AUTOSAR XML (schema 00048)
package /ComponentTypes
  swc implementation Can_Server_Implementation: behavior=Can_Server_InternalBehavior
    code-descriptors:
      code Default: artifact-descriptors=autosar-engineering-object=category=SWSRC
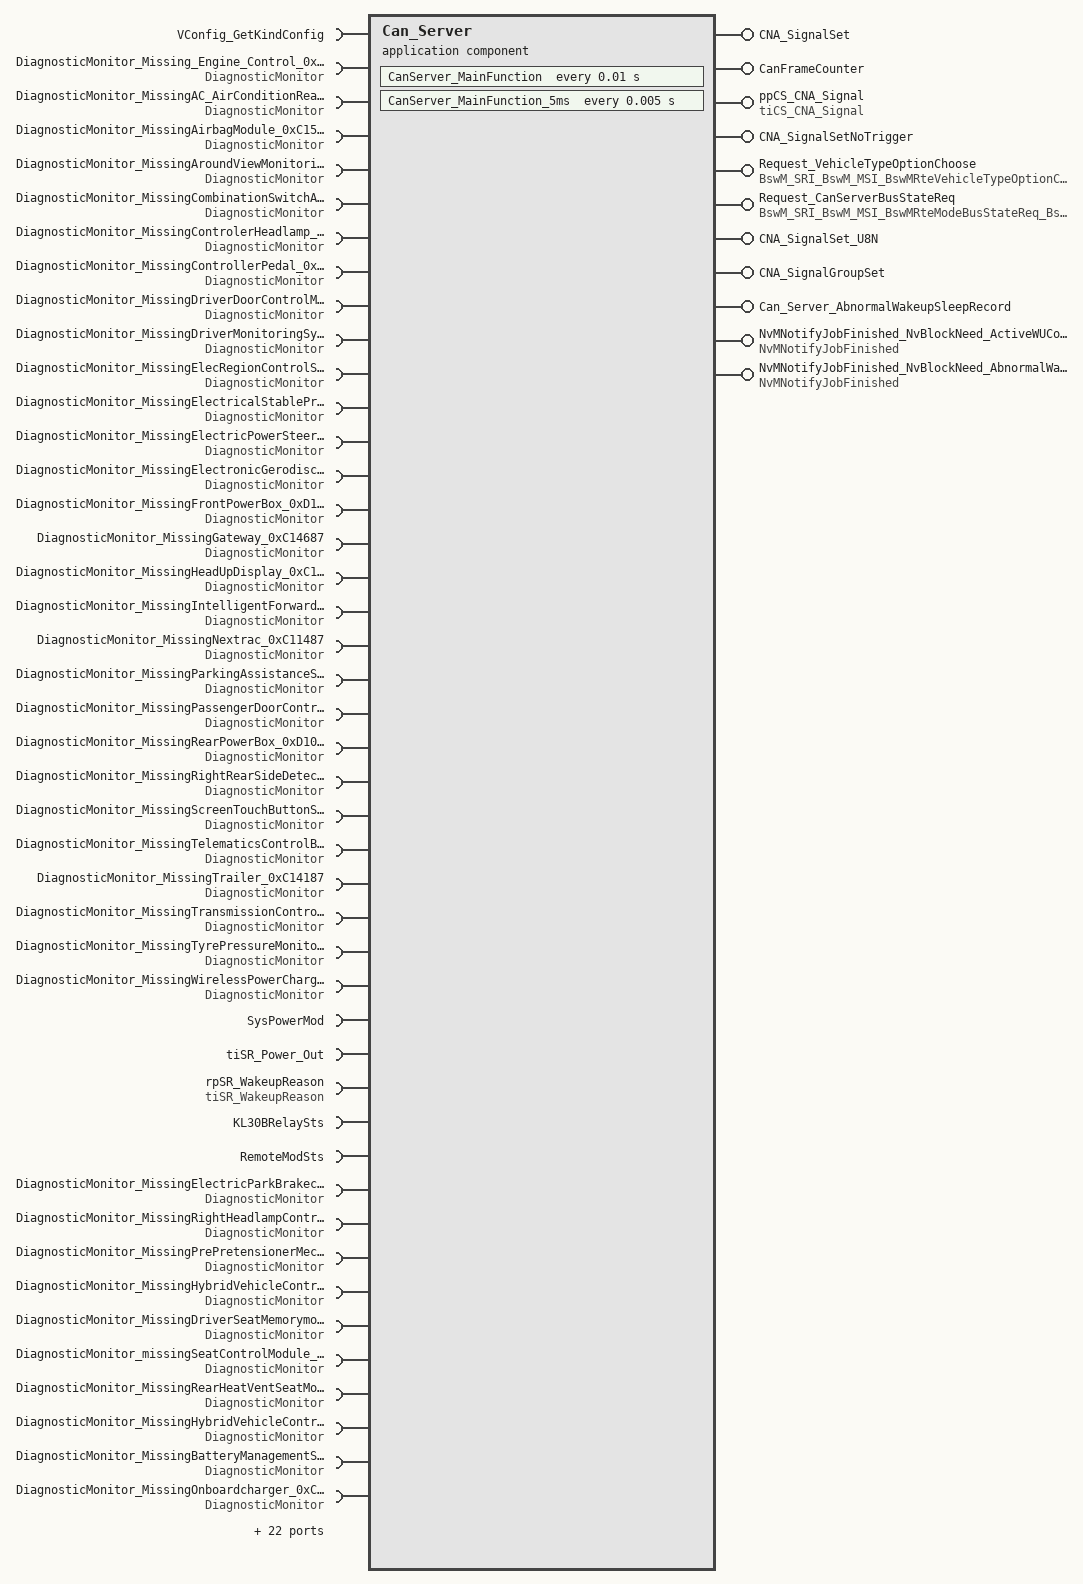
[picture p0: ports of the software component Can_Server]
  application sw component type Can_Server
    32 x require port:
      VConfig_GetKindConfig: client-com-spec=Operation_VConfig_GetKindConfig, required-interface=VConfig_GetKindConfig
      DiagnosticMonitor_Missing_Engine_Control_0xC10087: required-interface=DiagnosticMonitor
        required-com-specs:
          SetEventStatus
          ResetEventStatus
          ResetEventDebounceStatus
          GetEventUdsStatus
          GetEventStatus
          GetEventFailed
          GetEventTested
          GetDTCOfEvent
          GetFaultDetectionCounter
          GetEventFreezeFrameDataEx
          GetEventExtendedDataRecordEx
      DiagnosticMonitor_MissingAC_AirConditionRearFrontControlPanel_0xC16487: required-interface=DiagnosticMonitor
        required-com-specs:
          SetEventStatus
          ResetEventStatus
          ResetEventDebounceStatus
          GetEventUdsStatus
          GetEventStatus
          GetEventFailed
          GetEventTested
          GetDTCOfEvent
          GetFaultDetectionCounter
          GetEventFreezeFrameDataEx
          GetEventExtendedDataRecordEx
      DiagnosticMonitor_MissingAirbagModule_0xC15187: required-interface=DiagnosticMonitor
        required-com-specs:
          SetEventStatus
          ResetEventStatus
          ResetEventDebounceStatus
          GetEventUdsStatus
          GetEventStatus
          GetEventFailed
          GetEventTested
          GetDTCOfEvent
          GetFaultDetectionCounter
          GetEventFreezeFrameDataEx
          GetEventExtendedDataRecordEx
      DiagnosticMonitor_MissingAroundViewMonitoringSystem_0xD00487: required-interface=DiagnosticMonitor
        required-com-specs:
          SetEventStatus
          ResetEventStatus
          ResetEventDebounceStatus
          GetEventUdsStatus
          GetEventStatus
          GetEventFailed
          GetEventTested
          GetDTCOfEvent
          GetFaultDetectionCounter
          GetEventFreezeFrameDataEx
          GetEventExtendedDataRecordEx
      DiagnosticMonitor_MissingCombinationSwitchAssembly_0xD10687: required-interface=DiagnosticMonitor
        required-com-specs:
          SetEventStatus
          ResetEventStatus
          ResetEventDebounceStatus
          GetEventUdsStatus
          GetEventStatus
          GetEventFailed
          GetEventTested
          GetDTCOfEvent
          GetFaultDetectionCounter
          GetEventFreezeFrameDataEx
          GetEventExtendedDataRecordEx
      DiagnosticMonitor_MissingControlerHeadlamp_0xC24187: required-interface=DiagnosticMonitor
        required-com-specs:
          SetEventStatus
          ResetEventStatus
          ResetEventDebounceStatus
          GetEventUdsStatus
          GetEventStatus
          GetEventFailed
          GetEventTested
          GetDTCOfEvent
          GetFaultDetectionCounter
          GetEventFreezeFrameDataEx
          GetEventExtendedDataRecordEx
      DiagnosticMonitor_MissingControllerPedal_0xD00987: required-interface=DiagnosticMonitor
        required-com-specs:
          SetEventStatus
          ResetEventStatus
          ResetEventDebounceStatus
          GetEventUdsStatus
          GetEventStatus
          GetEventFailed
          GetEventTested
          GetDTCOfEvent
          GetFaultDetectionCounter
          GetEventFreezeFrameDataEx
          GetEventExtendedDataRecordEx
      DiagnosticMonitor_MissingDriverDoorControlModule_0xC19987: required-interface=DiagnosticMonitor
        required-com-specs:
          SetEventStatus
          ResetEventStatus
          ResetEventDebounceStatus
          GetEventUdsStatus
          GetEventStatus
          GetEventFailed
          GetEventTested
          GetDTCOfEvent
          GetFaultDetectionCounter
          GetEventFreezeFrameDataEx
          GetEventExtendedDataRecordEx
      DiagnosticMonitor_MissingDriverMonitoringSystem_0xC2B387: required-interface=DiagnosticMonitor
        required-com-specs:
          SetEventStatus
          ResetEventStatus
          ResetEventDebounceStatus
          GetEventUdsStatus
          GetEventStatus
          GetEventFailed
          GetEventTested
          GetDTCOfEvent
          GetFaultDetectionCounter
          GetEventFreezeFrameDataEx
          GetEventExtendedDataRecordEx
      DiagnosticMonitor_MissingElecRegionControlSystemBody_0xC14087: required-interface=DiagnosticMonitor
        required-com-specs:
          SetEventStatus
          ResetEventStatus
          ResetEventDebounceStatus
          GetEventUdsStatus
          GetEventStatus
          GetEventFailed
          GetEventTested
          GetDTCOfEvent
          GetFaultDetectionCounter
          GetEventFreezeFrameDataEx
          GetEventExtendedDataRecordEx
      DiagnosticMonitor_MissingElectricalStableProgram_0xC12287: required-interface=DiagnosticMonitor
        required-com-specs:
          SetEventStatus
          ResetEventStatus
          ResetEventDebounceStatus
          GetEventUdsStatus
          GetEventStatus
          GetEventFailed
          GetEventTested
          GetDTCOfEvent
          GetFaultDetectionCounter
          GetEventFreezeFrameDataEx
          GetEventExtendedDataRecordEx
      DiagnosticMonitor_MissingElectricPowerSteeringSystem_0xC13187: required-interface=DiagnosticMonitor
        required-com-specs:
          SetEventStatus
          ResetEventStatus
          ResetEventDebounceStatus
          GetEventUdsStatus
          GetEventStatus
          GetEventFailed
          GetEventTested
          GetDTCOfEvent
          GetFaultDetectionCounter
          GetEventFreezeFrameDataEx
          GetEventExtendedDataRecordEx
      DiagnosticMonitor_MissingElectronicGerodisc_0xC11587: required-interface=DiagnosticMonitor
        required-com-specs:
          SetEventStatus
          ResetEventStatus
          ResetEventDebounceStatus
          GetEventUdsStatus
          GetEventStatus
          GetEventFailed
          GetEventTested
          GetDTCOfEvent
          GetFaultDetectionCounter
          GetEventFreezeFrameDataEx
          GetEventExtendedDataRecordEx
      DiagnosticMonitor_MissingFrontPowerBox_0xD10887: required-interface=DiagnosticMonitor
        required-com-specs:
          SetEventStatus
          ResetEventStatus
          ResetEventDebounceStatus
          GetEventUdsStatus
          GetEventStatus
          GetEventFailed
          GetEventTested
          GetDTCOfEvent
          GetFaultDetectionCounter
          GetEventFreezeFrameDataEx
          GetEventExtendedDataRecordEx
      DiagnosticMonitor_MissingGateway_0xC14687: required-interface=DiagnosticMonitor
        required-com-specs:
          SetEventStatus
          ResetEventStatus
          ResetEventDebounceStatus
          GetEventUdsStatus
          GetEventStatus
          GetEventFailed
          GetEventTested
          GetDTCOfEvent
          GetFaultDetectionCounter
          GetEventFreezeFrameDataEx
          GetEventExtendedDataRecordEx
      DiagnosticMonitor_MissingHeadUpDisplay_0xC15887: required-interface=DiagnosticMonitor
        required-com-specs:
          SetEventStatus
          ResetEventStatus
          ResetEventDebounceStatus
          GetEventUdsStatus
          GetEventStatus
          GetEventFailed
          GetEventTested
          GetDTCOfEvent
          GetFaultDetectionCounter
          GetEventFreezeFrameDataEx
          GetEventExtendedDataRecordEx
      DiagnosticMonitor_MissingIntelligentForwardViewCamera_0xC14387: required-interface=DiagnosticMonitor
        required-com-specs:
          SetEventStatus
          ResetEventStatus
          ResetEventDebounceStatus
          GetEventUdsStatus
          GetEventStatus
          GetEventFailed
          GetEventTested
          GetDTCOfEvent
          GetFaultDetectionCounter
          GetEventFreezeFrameDataEx
          GetEventExtendedDataRecordEx
      DiagnosticMonitor_MissingNextrac_0xC11487: required-interface=DiagnosticMonitor
        required-com-specs:
          SetEventStatus
          ResetEventStatus
          ResetEventDebounceStatus
          GetEventUdsStatus
          GetEventStatus
          GetEventFailed
          GetEventTested
          GetDTCOfEvent
          GetFaultDetectionCounter
          GetEventFreezeFrameDataEx
          GetEventExtendedDataRecordEx
      DiagnosticMonitor_MissingParkingAssistanceSystem_0xC24387: required-interface=DiagnosticMonitor
        required-com-specs:
          SetEventStatus
          ResetEventStatus
          ResetEventDebounceStatus
          GetEventUdsStatus
          GetEventStatus
          GetEventFailed
          GetEventTested
          GetDTCOfEvent
          GetFaultDetectionCounter
          GetEventFreezeFrameDataEx
          GetEventExtendedDataRecordEx
      DiagnosticMonitor_MissingPassengerDoorControlModule_0xC20087: required-interface=DiagnosticMonitor
        required-com-specs:
          SetEventStatus
          ResetEventStatus
          ResetEventDebounceStatus
          GetEventUdsStatus
          GetEventStatus
          GetEventFailed
          GetEventTested
          GetDTCOfEvent
          GetFaultDetectionCounter
          GetEventFreezeFrameDataEx
          GetEventExtendedDataRecordEx
      DiagnosticMonitor_MissingRearPowerBox_0xD10987: required-interface=DiagnosticMonitor
        required-com-specs:
          SetEventStatus
          ResetEventStatus
          ResetEventDebounceStatus
          GetEventUdsStatus
          GetEventStatus
          GetEventFailed
          GetEventTested
          GetDTCOfEvent
          GetFaultDetectionCounter
          GetEventFreezeFrameDataEx
          GetEventExtendedDataRecordEx
      DiagnosticMonitor_MissingRightRearSideDetectionSystem_0xC23387: required-interface=DiagnosticMonitor
        required-com-specs:
          SetEventStatus
          ResetEventStatus
          ResetEventDebounceStatus
          GetEventUdsStatus
          GetEventStatus
          GetEventFailed
          GetEventTested
          GetDTCOfEvent
          GetFaultDetectionCounter
          GetEventFreezeFrameDataEx
          GetEventExtendedDataRecordEx
      DiagnosticMonitor_MissingScreenTouchButtonSwitchController_0xD01587: required-interface=DiagnosticMonitor
        required-com-specs:
          SetEventStatus
          ResetEventStatus
          ResetEventDebounceStatus
          GetEventUdsStatus
          GetEventStatus
          GetEventFailed
          GetEventTested
          GetDTCOfEvent
          GetFaultDetectionCounter
          GetEventFreezeFrameDataEx
          GetEventExtendedDataRecordEx
      DiagnosticMonitor_MissingTelematicsControlBox_0xC19887: required-interface=DiagnosticMonitor
        required-com-specs:
          SetEventStatus
          ResetEventStatus
          ResetEventDebounceStatus
          GetEventUdsStatus
          GetEventStatus
          GetEventFailed
          GetEventTested
          GetDTCOfEvent
          GetFaultDetectionCounter
          GetEventFreezeFrameDataEx
          GetEventExtendedDataRecordEx
      DiagnosticMonitor_MissingTrailer_0xC14187: required-interface=DiagnosticMonitor
        required-com-specs:
          SetEventStatus
          ResetEventStatus
          ResetEventDebounceStatus
          GetEventUdsStatus
          GetEventStatus
          GetEventFailed
          GetEventTested
          GetDTCOfEvent
          GetFaultDetectionCounter
          GetEventFreezeFrameDataEx
          GetEventExtendedDataRecordEx
      DiagnosticMonitor_MissingTransmissionControlUntilPTCAN_0xC10187: required-interface=DiagnosticMonitor
        required-com-specs:
          SetEventStatus
          ResetEventStatus
          ResetEventDebounceStatus
          GetEventUdsStatus
          GetEventStatus
          GetEventFailed
          GetEventTested
          GetDTCOfEvent
          GetFaultDetectionCounter
          GetEventFreezeFrameDataEx
          GetEventExtendedDataRecordEx
      DiagnosticMonitor_MissingTyrePressureMonitoringSystem_0xC12787: required-interface=DiagnosticMonitor
        required-com-specs:
          SetEventStatus
          ResetEventStatus
          ResetEventDebounceStatus
          GetEventUdsStatus
          GetEventStatus
          GetEventFailed
          GetEventTested
          GetDTCOfEvent
          GetFaultDetectionCounter
          GetEventFreezeFrameDataEx
          GetEventExtendedDataRecordEx
      DiagnosticMonitor_MissingWirelessPowerCharger_0xD02987: required-interface=DiagnosticMonitor
        required-com-specs:
          SetEventStatus
          ResetEventStatus
          ResetEventDebounceStatus
          GetEventUdsStatus
          GetEventStatus
          GetEventFailed
          GetEventTested
          GetDTCOfEvent
          GetFaultDetectionCounter
          GetEventFreezeFrameDataEx
          GetEventExtendedDataRecordEx
      SysPowerMod: nonqueued-receiver-com-spec{data-element=SysPowerMod, alive-timeout=0.5, filter=data-filter-type=ALWAYS, handle-never-received=true, init-value=0}, required-interface=SysPowerMod
      tiSR_Power_Out: nonqueued-receiver-com-spec{data-element=SystemStateOut, filter=data-filter-type=ALWAYS, init-value=constant-reference=PowerOutInit}, required-interface=tiSR_Power_Out
      rpSR_WakeupReason: nonqueued-receiver-com-spec{data-element=data, filter=data-filter-type=ALWAYS, init-value=0}, required-interface=tiSR_WakeupReason
    provide port CNA_SignalSet: server-com-spec{operation=Operation, queue-length=1}, provided-interface=CNA_SignalSet
    22 x require port:
      KL30BRelaySts: nonqueued-receiver-com-spec{data-element=KL30BRelaySts, filter=data-filter-type=ALWAYS, init-value=0}, required-interface=KL30BRelaySts
      RemoteModSts: nonqueued-receiver-com-spec{data-element=RemoteModSts, filter=data-filter-type=ALWAYS, init-value=0}, required-interface=RemoteModSts
      DiagnosticMonitor_MissingElectricParkBrakecontroller_0xC12887: required-interface=DiagnosticMonitor
        required-com-specs:
          GetEventExtendedDataRecordEx
          GetEventFreezeFrameDataEx
          GetFaultDetectionCounter
          GetDTCOfEvent
          GetEventTested
          GetEventFailed
          GetEventStatus
          GetEventUdsStatus
          ResetEventDebounceStatus
          ResetEventStatus
          SetEventStatus
      DiagnosticMonitor_MissingRightHeadlampControlModule_0xC24287: required-interface=DiagnosticMonitor
        required-com-specs:
          GetEventExtendedDataRecordEx
          GetEventFreezeFrameDataEx
          GetFaultDetectionCounter
          GetDTCOfEvent
          GetEventTested
          GetEventFailed
          GetEventStatus
          GetEventUdsStatus
          ResetEventDebounceStatus
          ResetEventStatus
          SetEventStatus
      DiagnosticMonitor_MissingPrePretensionerMechatronicIntegrated_0xD10B87: required-interface=DiagnosticMonitor
        required-com-specs:
          GetEventExtendedDataRecordEx
          GetEventFreezeFrameDataEx
          GetFaultDetectionCounter
          GetDTCOfEvent
          GetEventTested
          GetEventFailed
          GetEventStatus
          GetEventUdsStatus
          ResetEventDebounceStatus
          ResetEventStatus
          SetEventStatus
      DiagnosticMonitor_MissingHybridVehicleControlUnitVehiclecontrolunit_PTCAN_0xD02687: required-interface=DiagnosticMonitor
        required-com-specs:
          GetEventExtendedDataRecordEx
          GetEventFreezeFrameDataEx
          GetFaultDetectionCounter
          GetDTCOfEvent
          GetEventTested
          GetEventFailed
          GetEventStatus
          GetEventUdsStatus
          ResetEventDebounceStatus
          ResetEventStatus
          SetEventStatus
      DiagnosticMonitor_MissingDriverSeatMemorymodule_0xC20887: required-interface=DiagnosticMonitor
        required-com-specs:
          GetEventExtendedDataRecordEx
          GetEventFreezeFrameDataEx
          GetFaultDetectionCounter
          GetDTCOfEvent
          GetEventTested
          GetEventFailed
          GetEventStatus
          GetEventUdsStatus
          ResetEventDebounceStatus
          ResetEventStatus
          SetEventStatus
      DiagnosticMonitor_missingSeatControlModule_0xC24687: required-interface=DiagnosticMonitor
        required-com-specs:
          GetEventExtendedDataRecordEx
          GetEventFreezeFrameDataEx
          GetFaultDetectionCounter
          GetDTCOfEvent
          GetEventTested
          GetEventFailed
          GetEventStatus
          GetEventUdsStatus
          ResetEventDebounceStatus
          ResetEventStatus
          SetEventStatus
      DiagnosticMonitor_MissingRearHeatVentSeatModule_0xC24787: required-interface=DiagnosticMonitor
        required-com-specs:
          GetEventExtendedDataRecordEx
          GetEventFreezeFrameDataEx
          GetFaultDetectionCounter
          GetDTCOfEvent
          GetEventTested
          GetEventFailed
          GetEventStatus
          GetEventUdsStatus
          ResetEventDebounceStatus
          ResetEventStatus
          SetEventStatus
      DiagnosticMonitor_MissingHybridVehicleControlUnitVehiclecontrolunit_HCCAN_0xC29387: required-interface=DiagnosticMonitor
        required-com-specs:
          GetEventExtendedDataRecordEx
          GetEventFreezeFrameDataEx
          GetFaultDetectionCounter
          GetDTCOfEvent
          GetEventTested
          GetEventFailed
          GetEventStatus
          GetEventUdsStatus
          ResetEventDebounceStatus
          ResetEventStatus
          SetEventStatus
      DiagnosticMonitor_MissingBatteryManagementSystem_0xC11187: required-interface=DiagnosticMonitor
        required-com-specs:
          GetEventExtendedDataRecordEx
          GetEventFreezeFrameDataEx
          GetFaultDetectionCounter
          GetDTCOfEvent
          GetEventTested
          GetEventFailed
          GetEventStatus
          GetEventUdsStatus
          ResetEventDebounceStatus
          ResetEventStatus
          SetEventStatus
      DiagnosticMonitor_MissingOnboardcharger_0xC1BB87: required-interface=DiagnosticMonitor
        required-com-specs:
          GetEventExtendedDataRecordEx
          GetEventFreezeFrameDataEx
          GetFaultDetectionCounter
          GetDTCOfEvent
          GetEventTested
          GetEventFailed
          GetEventStatus
          GetEventUdsStatus
          ResetEventDebounceStatus
          ResetEventStatus
          SetEventStatus
      DiagnosticMonitor_missingAdaptiveCruiseControlsystemRadarControlModule_0xC10487: required-interface=DiagnosticMonitor
        required-com-specs:
          GetEventExtendedDataRecordEx
          GetEventFreezeFrameDataEx
          GetFaultDetectionCounter
          GetDTCOfEvent
          GetEventTested
          GetEventFailed
          GetEventStatus
          GetEventUdsStatus
          ResetEventDebounceStatus
          ResetEventStatus
          SetEventStatus
      DiagnosticMonitor_MissingPowerLiftGatemodule_0xC23087: required-interface=DiagnosticMonitor
        required-com-specs:
          GetEventExtendedDataRecordEx
          GetEventFreezeFrameDataEx
          GetFaultDetectionCounter
          GetDTCOfEvent
          GetEventTested
          GetEventFailed
          GetEventStatus
          GetEventUdsStatus
          ResetEventDebounceStatus
          ResetEventStatus
          SetEventStatus
      DiagnosticMonitor_MissingIntelligentDrivingController_Level2_0xC15C87: required-interface=DiagnosticMonitor
        required-com-specs:
          GetEventExtendedDataRecordEx
          GetEventFreezeFrameDataEx
          GetFaultDetectionCounter
          GetDTCOfEvent
          GetEventTested
          GetEventFailed
          GetEventStatus
          GetEventUdsStatus
          ResetEventDebounceStatus
          ResetEventStatus
          SetEventStatus
      DiagnosticMonitor_missingRightCornerRadar_0xC2B587: required-interface=DiagnosticMonitor
        required-com-specs:
          GetEventExtendedDataRecordEx
          GetEventFreezeFrameDataEx
          GetFaultDetectionCounter
          GetDTCOfEvent
          GetEventTested
          GetEventFailed
          GetEventStatus
          GetEventUdsStatus
          ResetEventDebounceStatus
          ResetEventStatus
          SetEventStatus
      DiagnosticMonitor_MissingIbooster_0xC25E87: required-interface=DiagnosticMonitor
        required-com-specs:
          GetEventExtendedDataRecordEx
          GetEventFreezeFrameDataEx
          GetFaultDetectionCounter
          GetDTCOfEvent
          GetEventTested
          GetEventFailed
          GetEventStatus
          GetEventUdsStatus
          ResetEventDebounceStatus
          ResetEventStatus
          SetEventStatus
      DiagnosticMonitor_BusOff_0xC07388: required-interface=DiagnosticMonitor
        required-com-specs:
          GetEventExtendedDataRecordEx
          GetEventFreezeFrameDataEx
          GetFaultDetectionCounter
          GetDTCOfEvent
          GetEventTested
          GetEventFailed
          GetEventStatus
          GetEventUdsStatus
          ResetEventDebounceStatus
          ResetEventStatus
          SetEventStatus
      rpCS_IPC_TransmitSignal: client-com-spec=Callback, required-interface=tiCS_IPC_TransmitSignal
      rpCS_IPC_Tx_E2E_CanMsg_HUT_IP2: client-com-spec=Callback, required-interface=tiCS_IPC_Tx_E2E_CanMsg_HUT_IP2
      rpCS_IPC_API_SetEventTxSignalBuffer: client-com-spec=Operation, required-interface=tiCS_IPC_API_SetEventTxSignalBuffer
      rpCS_IPC_Tx_E2E_CanMsg_HUT32: client-com-spec=CallBack, required-interface=tiCS_IPC_Tx_E2E_CanMsg_HUT32
    provide port CanFrameCounter: provided-interface=CanFrameCounter
      provided-com-specs:
        operation=Can_ECM2_Counter, queue-length=1
        operation=Can_ESP_FD2_Counter, queue-length=1
        operation=Can_ABS3_Counter, queue-length=1
    require port SysPowerModVld: nonqueued-receiver-com-spec{data-element=SysPowerModVld, alive-timeout=0.5, filter=data-filter-type=ALWAYS, handle-never-received=true, init-value=0}, required-interface=SysPowerModVld
    require port ClearDTC_Service0x14: nonqueued-receiver-com-spec{data-element=StatusFlag, filter=data-filter-type=ALWAYS, init-value=0}, required-interface=ClearDTC_Service0x14
    provide port ppCS_CNA_Signal: server-com-spec{operation=CallBack, queue-length=1}, provided-interface=tiCS_CNA_Signal
    require port rpCS_ComEx: required-com-specs=[SendSignal, ReceiveSignal, GetRxE2EStatus], required-interface=ComEx
    require port DcmDiagnosticSessionControl: mode-switch-receiver-com-spec=DcmDiagnosticSessionControl, required-interface=DcmDiagnosticSessionControl
    require port Can_Server_piDiagMonitorReInitFlag: nonqueued-receiver-com-spec{data-element=ChangeCounter, init-value=0}, required-interface=piDiagMonitorReInitFlag
    4 x provide port:
      CNA_SignalSetNoTrigger: server-com-spec{operation=Operation, queue-length=1}, provided-interface=CNA_SignalSetNoTrigger
      Request_VehicleTypeOptionChoose: nonqueued-sender-com-spec=requestedMode, provided-interface=BswM_SRI_BswM_MSI_BswMRteVehicleTypeOptionChoose_BswM_MDGP_BswMRteVehicleTypeOptionChoose
      Request_CanServerBusStateReq: nonqueued-sender-com-spec=requestedMode, provided-interface=BswM_SRI_BswM_MSI_BswMRteModeBusStateReq_BswM_MDGP_BswMRteModeBusStateReq
      CNA_SignalSet_U8N: server-com-spec{operation=Operation, queue-length=1}, provided-interface=CNA_SignalSet_U8N
    require port DiagnosticMonitor_MissingDepthOfWaterDetectionModule_0xD12387: required-interface=DiagnosticMonitor
      required-com-specs:
        GetEventExtendedDataRecordEx
        GetEventFreezeFrameDataEx
        GetFaultDetectionCounter
        GetDTCOfEvent
        GetEventTested
        GetEventFailed
        GetEventStatus
        GetEventUdsStatus
        ResetEventDebounceStatus
        ResetEventStatus
        SetEventStatus
    provide port CNA_SignalGroupSet: server-com-spec{operation=Operation, queue-length=1}, provided-interface=CNA_SignalGroupSet
    require port Vconfig_GetKindBuffers: nonqueued-receiver-com-spec{data-element=AllKinds, filter=data-filter-type=ALWAYS, init-value=600 x 0}, required-interface=Vconfig_GetKindBuffers
    require port cpCS_IRTC_Service: required-com-specs=[GetUTCTimeInMillis, UTC2PerpetualCalendar], required-interface=IRTC_Service
    require port rpSR_RTCTimer: required-interface=if_RTC
      required-com-specs:
        data-element=SleepDateTime, filter=data-filter-type=ALWAYS
        data-element=UtcTime, filter=data-filter-type=ALWAYS
    provide port Can_Server_AbnormalWakeupSleepRecord: server-com-spec{operation=Get, queue-length=1}, provided-interface=Can_Server_AbnormalWakeupSleepRecord
    require port DiagnosticMonitor_AbnormalWakeupSleep_0xF01200: required-interface=DiagnosticMonitor
      required-com-specs:
        GetEventExtendedDataRecordEx
        GetEventFreezeFrameDataEx
        GetFaultDetectionCounter
        GetDTCOfEvent
        GetEventTested
        GetEventFailed
        GetEventStatus
        GetEventUdsStatus
        ResetEventDebounceStatus
        ResetEventStatus
        SetEventStatus
    provide port NvMNotifyJobFinished_NvBlockNeed_ActiveWUCounter: server-com-spec{operation=JobFinished, queue-length=1}, provided-interface=NvMNotifyJobFinished
    require port NvMService_AC2_SRBS_NvBlockNeed_ActiveWUCounter: required-com-specs=[WriteBlock, SetRamBlockStatus, ReadBlock, GetErrorStatus], required-interface=NvMService_AC2_SRBS
    provide port NvMNotifyJobFinished_NvBlockNeed_AbnormalWakeupSleepRecords: server-com-spec{operation=JobFinished, queue-length=1}, provided-interface=NvMNotifyJobFinished
    require port NvMService_AC2_SRBS_NvBlockNeed_AbnormalWakeupSleepRecords: required-com-specs=[WriteBlock, SetRamBlockStatus, ReadBlock, GetErrorStatus], required-interface=NvMService_AC2_SRBS
    behavior Can_Server_InternalBehavior
      ar-typed-per-instance-memorys:
        data NvBlockNeed_ActiveWUCounter_MirrorBlock: sw-calibration-access=READ-ONLY, type=uint8
        data NvBlockNeed_AbnormalWakeupSleepRecords_MirrorBlock: sw-calibration-access=READ-ONLY, type=A_80Bytes
      init event CanServer_InitEvent: start-on-event=CanServer_Init
      timing event TMT_CanServer_MainFunction: start-on-event=CanServer_MainFunction, period=0.01
      operation invoked event OIT_ComNoAction_CNA_SignalSet_Operation: start-on-event=CNA_SignalSet, operation=CNA_SignalSet.Operation
      timing event TMT_CanServer_MainFunction_5ms: start-on-event=CanServer_MainFunction_5ms, period=0.005
      10 x operation invoked event:
        OIT_CanFrameCounter_Can_ECM2_Counter_CanFrameCounter_Can_ECM2_Counter: start-on-event=CanFrameCounter_Can_ECM2_Counter, operation=CanFrameCounter.Can_ECM2_Counter
        OIT_CanFrameCounter_Can_ESP_FD2_Counter_CanFrameCounter_Can_ESP_FD2_Counter: start-on-event=CanFrameCounter_Can_ESP_FD2_Counter, operation=CanFrameCounter.Can_ESP_FD2_Counter
        OIT_CanFrameCounter_Can_ABS3_Counter_CanFrameCounter_Can_ABS3_Counter: start-on-event=CanFrameCounter_Can_ABS3_Counter, operation=CanFrameCounter.Can_ABS3_Counter
        OIT_CNA_SignalCallBack_ppCS_CNA_Signal_CallBack: start-on-event=CNA_SignalCallBack, operation=ppCS_CNA_Signal.CallBack
        OIT_CNA_SignalSetNoTrigger_CNA_SignalSetNoTrigger_Operation: start-on-event=CNA_SignalSetNoTrigger, operation=CNA_SignalSetNoTrigger.Operation
        OIT_CNA_SignalSet_U8N_CNA_SignalSet_U8N_Operation: start-on-event=CNA_SignalSet_U8N, operation=CNA_SignalSet_U8N.Operation
        OIT_Runnable_CNA_SignalGroupSet_Operation: start-on-event=CNA_SignalGroupSet, operation=CNA_SignalGroupSet.Operation
        OIT_Can_Server_AbnormalWakeupSleepRecord_Get_Can_Server_AbnormalWakeupSleepRecord_Get: start-on-event=Can_Server_AbnormalWakeupSleepRecord_Get, operation=Can_Server_AbnormalWakeupSleepRecord.Get
        OIT_NvMNotifyJobFinished_NvBlockNeed_ActiveWUCounter_JobFinished_NvMNotifyJobFinished_NvBlockNeed_ActiveWUCounter_JobFinished: start-on-event=NvMNotifyJobFinished_NvBlockNeed_ActiveWUCounter_JobFinished, operation=NvMNotifyJobFinished_NvBlockNeed_ActiveWUCounter.JobFinished
        OIT_NvMNotifyJobFinished_NvBlockNeed_AbnormalWakeupSleepRecords_JobFinished_NvMNotifyJobFinished_NvBlockNeed_AbnormalWak05665798: start-on-event=NvMNotifyJobFinished_NvBlockNeed_AbnormalWakeupSleepRecords_JobFinished, operation=NvMNotifyJobFinished_NvBlockNeed_AbnormalWakeupSleepRecords.JobFinished
      port-api-options:
        enable-take-address=false, error-handling=NO-TRANSFORMER-ERROR-HANDLING, indirect-api=false, port=ppCS_CNA_Signal
        enable-take-address=false, error-handling=NO-TRANSFORMER-ERROR-HANDLING, indirect-api=false, port=rpCS_ComEx
      14 x runnable:
        CanServer_Init
          data-receive-point-by-arguments:
            access REC_Vconfig_GetKindBuffers_Kind600Bytes: accessed-variable=Vconfig_GetKindBuffers.AllKinds
          data-send-points:
            access SEND_Request_VehicleTypeOptionChoose_requestedMode: accessed-variable=Request_VehicleTypeOptionChoose.requestedMode
        CanServer_MainFunction: mode-access-point=DcmDiagnosticSessionControl.DcmDiagnosticSessionControl
          data-receive-point-by-arguments:
            8 x access:
              REC_SysPowerMod_SysPowerMod: accessed-variable=SysPowerMod.SysPowerMod
              REC_tiSR_Power_Out_SystemStateOut: accessed-variable=tiSR_Power_Out.SystemStateOut
              REC_rpSR_WakeupReason_data: accessed-variable=rpSR_WakeupReason.data
              REC_KL30BRelaySts_KL30BRelaySts: accessed-variable=KL30BRelaySts.KL30BRelaySts
              REC_RemoteModSts_RemoteModSts: accessed-variable=RemoteModSts.RemoteModSts
              REC_SysPowerModVld_SysPowerModVld: accessed-variable=SysPowerModVld.SysPowerModVld
              REC_Can_Server_piDiagMonitorReInitFlag_ChangeCounter: accessed-variable=Can_Server_piDiagMonitorReInitFlag.ChangeCounter
              REC_rpSR_RTCTimer_UtcTime: accessed-variable=rpSR_RTCTimer.UtcTime
          data-send-points:
            access SEND_Request_CanServerBusStateReq_requestedMode: accessed-variable=Request_CanServerBusStateReq.requestedMode
          511 x sync call:
            SC_DiagnosticMonitor_Missing_Engine_Control_0xC10087_GetDTCOfEvent: operation=DiagnosticMonitor_Missing_Engine_Control_0xC10087.GetDTCOfEvent
            SC_DiagnosticMonitor_Missing_Engine_Control_0xC10087_GetEventExtendedDataRecordEx: operation=DiagnosticMonitor_Missing_Engine_Control_0xC10087.GetEventExtendedDataRecordEx
            SC_DiagnosticMonitor_Missing_Engine_Control_0xC10087_GetEventFailed: operation=DiagnosticMonitor_Missing_Engine_Control_0xC10087.GetEventFailed
            SC_DiagnosticMonitor_Missing_Engine_Control_0xC10087_GetEventFreezeFrameDataEx: operation=DiagnosticMonitor_Missing_Engine_Control_0xC10087.GetEventFreezeFrameDataEx
            SC_DiagnosticMonitor_Missing_Engine_Control_0xC10087_GetEventStatus: operation=DiagnosticMonitor_Missing_Engine_Control_0xC10087.GetEventStatus
            SC_DiagnosticMonitor_Missing_Engine_Control_0xC10087_GetEventTested: operation=DiagnosticMonitor_Missing_Engine_Control_0xC10087.GetEventTested
            SC_DiagnosticMonitor_Missing_Engine_Control_0xC10087_GetEventUdsStatus: operation=DiagnosticMonitor_Missing_Engine_Control_0xC10087.GetEventUdsStatus
            SC_DiagnosticMonitor_Missing_Engine_Control_0xC10087_GetFaultDetectionCounter: operation=DiagnosticMonitor_Missing_Engine_Control_0xC10087.GetFaultDetectionCounter
            SC_DiagnosticMonitor_Missing_Engine_Control_0xC10087_ResetEventDebounceStatus: operation=DiagnosticMonitor_Missing_Engine_Control_0xC10087.ResetEventDebounceStatus
            SC_DiagnosticMonitor_Missing_Engine_Control_0xC10087_ResetEventStatus: operation=DiagnosticMonitor_Missing_Engine_Control_0xC10087.ResetEventStatus
            SC_DiagnosticMonitor_Missing_Engine_Control_0xC10087_SetEventStatus: operation=DiagnosticMonitor_Missing_Engine_Control_0xC10087.SetEventStatus
            SC_DiagnosticMonitor_MissingAC_AirConditionRearFrontControlPanel_0xC16487_GetDTCOfEvent: operation=DiagnosticMonitor_MissingAC_AirConditionRearFrontControlPanel_0xC16487.GetDTCOfEvent
            SC_DiagnosticMonitor_MissingAC_AirConditionRearFrontControlPanel_0xC16487_GetEventExtendedDataRecordEx: operation=DiagnosticMonitor_MissingAC_AirConditionRearFrontControlPanel_0xC16487.GetEventExtendedDataRecordEx
            SC_DiagnosticMonitor_MissingAC_AirConditionRearFrontControlPanel_0xC16487_GetEventFailed: operation=DiagnosticMonitor_MissingAC_AirConditionRearFrontControlPanel_0xC16487.GetEventFailed
            SC_DiagnosticMonitor_MissingAC_AirConditionRearFrontControlPanel_0xC16487_GetEventFreezeFrameDataEx: operation=DiagnosticMonitor_MissingAC_AirConditionRearFrontControlPanel_0xC16487.GetEventFreezeFrameDataEx
            SC_DiagnosticMonitor_MissingAC_AirConditionRearFrontControlPanel_0xC16487_GetEventStatus: operation=DiagnosticMonitor_MissingAC_AirConditionRearFrontControlPanel_0xC16487.GetEventStatus
            SC_DiagnosticMonitor_MissingAC_AirConditionRearFrontControlPanel_0xC16487_GetEventTested: operation=DiagnosticMonitor_MissingAC_AirConditionRearFrontControlPanel_0xC16487.GetEventTested
            SC_DiagnosticMonitor_MissingAC_AirConditionRearFrontControlPanel_0xC16487_GetEventUdsStatus: operation=DiagnosticMonitor_MissingAC_AirConditionRearFrontControlPanel_0xC16487.GetEventUdsStatus
            SC_DiagnosticMonitor_MissingAC_AirConditionRearFrontControlPanel_0xC16487_GetFaultDetectionCounter: operation=DiagnosticMonitor_MissingAC_AirConditionRearFrontControlPanel_0xC16487.GetFaultDetectionCounter
            SC_DiagnosticMonitor_MissingAC_AirConditionRearFrontControlPanel_0xC16487_ResetEventDebounceStatus: operation=DiagnosticMonitor_MissingAC_AirConditionRearFrontControlPanel_0xC16487.ResetEventDebounceStatus
            SC_DiagnosticMonitor_MissingAC_AirConditionRearFrontControlPanel_0xC16487_ResetEventStatus: operation=DiagnosticMonitor_MissingAC_AirConditionRearFrontControlPanel_0xC16487.ResetEventStatus
            SC_DiagnosticMonitor_MissingAC_AirConditionRearFrontControlPanel_0xC16487_SetEventStatus: operation=DiagnosticMonitor_MissingAC_AirConditionRearFrontControlPanel_0xC16487.SetEventStatus
            SC_DiagnosticMonitor_MissingAirbagModule_0xD00087_GetDTCOfEvent: operation=DiagnosticMonitor_MissingAirbagModule_0xC15187.GetDTCOfEvent
            SC_DiagnosticMonitor_MissingAirbagModule_0xD00087_GetEventExtendedDataRecordEx: operation=DiagnosticMonitor_MissingAirbagModule_0xC15187.GetEventExtendedDataRecordEx
            SC_DiagnosticMonitor_MissingAirbagModule_0xD00087_GetEventFailed: operation=DiagnosticMonitor_MissingAirbagModule_0xC15187.GetEventFailed
            SC_DiagnosticMonitor_MissingAirbagModule_0xD00087_GetEventFreezeFrameDataEx: operation=DiagnosticMonitor_MissingAirbagModule_0xC15187.GetEventFreezeFrameDataEx
            SC_DiagnosticMonitor_MissingAirbagModule_0xD00087_GetEventStatus: operation=DiagnosticMonitor_MissingAirbagModule_0xC15187.GetEventStatus
            SC_DiagnosticMonitor_MissingAirbagModule_0xD00087_GetEventTested: operation=DiagnosticMonitor_MissingAirbagModule_0xC15187.GetEventTested
            SC_DiagnosticMonitor_MissingAirbagModule_0xD00087_GetEventUdsStatus: operation=DiagnosticMonitor_MissingAirbagModule_0xC15187.GetEventUdsStatus
            SC_DiagnosticMonitor_MissingAirbagModule_0xD00087_GetFaultDetectionCounter: operation=DiagnosticMonitor_MissingAirbagModule_0xC15187.GetFaultDetectionCounter
            SC_DiagnosticMonitor_MissingAirbagModule_0xD00087_ResetEventDebounceStatus: operation=DiagnosticMonitor_MissingAirbagModule_0xC15187.ResetEventDebounceStatus
            SC_DiagnosticMonitor_MissingAirbagModule_0xD00087_ResetEventStatus: operation=DiagnosticMonitor_MissingAirbagModule_0xC15187.ResetEventStatus
            SC_DiagnosticMonitor_MissingAirbagModule_0xD00087_SetEventStatus: operation=DiagnosticMonitor_MissingAirbagModule_0xC15187.SetEventStatus
            SC_DiagnosticMonitor_MissingAroundViewMonitoringSystem_0xD00487_GetDTCOfEvent: operation=DiagnosticMonitor_MissingAroundViewMonitoringSystem_0xD00487.GetDTCOfEvent
            SC_DiagnosticMonitor_MissingAroundViewMonitoringSystem_0xD00487_GetEventExtendedDataRecordEx: operation=DiagnosticMonitor_MissingAroundViewMonitoringSystem_0xD00487.GetEventExtendedDataRecordEx
            SC_DiagnosticMonitor_MissingAroundViewMonitoringSystem_0xD00487_GetEventFailed: operation=DiagnosticMonitor_MissingAroundViewMonitoringSystem_0xD00487.GetEventFailed
            SC_DiagnosticMonitor_MissingAroundViewMonitoringSystem_0xD00487_GetEventFreezeFrameDataEx: operation=DiagnosticMonitor_MissingAroundViewMonitoringSystem_0xD00487.GetEventFreezeFrameDataEx
            SC_DiagnosticMonitor_MissingAroundViewMonitoringSystem_0xD00487_GetEventStatus: operation=DiagnosticMonitor_MissingAroundViewMonitoringSystem_0xD00487.GetEventStatus
            SC_DiagnosticMonitor_MissingAroundViewMonitoringSystem_0xD00487_GetEventTested: operation=DiagnosticMonitor_MissingAroundViewMonitoringSystem_0xD00487.GetEventTested
            SC_DiagnosticMonitor_MissingAroundViewMonitoringSystem_0xD00487_GetEventUdsStatus: operation=DiagnosticMonitor_MissingAroundViewMonitoringSystem_0xD00487.GetEventUdsStatus
            SC_DiagnosticMonitor_MissingAroundViewMonitoringSystem_0xD00487_GetFaultDetectionCounter: operation=DiagnosticMonitor_MissingAroundViewMonitoringSystem_0xD00487.GetFaultDetectionCounter
            SC_DiagnosticMonitor_MissingAroundViewMonitoringSystem_0xD00487_ResetEventDebounceStatus: operation=DiagnosticMonitor_MissingAroundViewMonitoringSystem_0xD00487.ResetEventDebounceStatus
            SC_DiagnosticMonitor_MissingAroundViewMonitoringSystem_0xD00487_ResetEventStatus: operation=DiagnosticMonitor_MissingAroundViewMonitoringSystem_0xD00487.ResetEventStatus
            SC_DiagnosticMonitor_MissingAroundViewMonitoringSystem_0xD00487_SetEventStatus: operation=DiagnosticMonitor_MissingAroundViewMonitoringSystem_0xD00487.SetEventStatus
            SC_DiagnosticMonitor_MissingCombinationSwitchAssembly_0xD10687_GetDTCOfEvent: operation=DiagnosticMonitor_MissingCombinationSwitchAssembly_0xD10687.GetDTCOfEvent
            SC_DiagnosticMonitor_MissingCombinationSwitchAssembly_0xD10687_GetEventExtendedDataRecordEx: operation=DiagnosticMonitor_MissingCombinationSwitchAssembly_0xD10687.GetEventExtendedDataRecordEx
            SC_DiagnosticMonitor_MissingCombinationSwitchAssembly_0xD10687_GetEventFailed: operation=DiagnosticMonitor_MissingCombinationSwitchAssembly_0xD10687.GetEventFailed
            SC_DiagnosticMonitor_MissingCombinationSwitchAssembly_0xD10687_GetEventFreezeFrameDataEx: operation=DiagnosticMonitor_MissingCombinationSwitchAssembly_0xD10687.GetEventFreezeFrameDataEx
            SC_DiagnosticMonitor_MissingCombinationSwitchAssembly_0xD10687_GetEventStatus: operation=DiagnosticMonitor_MissingCombinationSwitchAssembly_0xD10687.GetEventStatus
            SC_DiagnosticMonitor_MissingCombinationSwitchAssembly_0xD10687_GetEventTested: operation=DiagnosticMonitor_MissingCombinationSwitchAssembly_0xD10687.GetEventTested
            SC_DiagnosticMonitor_MissingCombinationSwitchAssembly_0xD10687_GetEventUdsStatus: operation=DiagnosticMonitor_MissingCombinationSwitchAssembly_0xD10687.GetEventUdsStatus
            SC_DiagnosticMonitor_MissingCombinationSwitchAssembly_0xD10687_GetFaultDetectionCounter: operation=DiagnosticMonitor_MissingCombinationSwitchAssembly_0xD10687.GetFaultDetectionCounter
            SC_DiagnosticMonitor_MissingCombinationSwitchAssembly_0xD10687_ResetEventDebounceStatus: operation=DiagnosticMonitor_MissingCombinationSwitchAssembly_0xD10687.ResetEventDebounceStatus
            SC_DiagnosticMonitor_MissingCombinationSwitchAssembly_0xD10687_ResetEventStatus: operation=DiagnosticMonitor_MissingCombinationSwitchAssembly_0xD10687.ResetEventStatus
            SC_DiagnosticMonitor_MissingCombinationSwitchAssembly_0xD10687_SetEventStatus: operation=DiagnosticMonitor_MissingCombinationSwitchAssembly_0xD10687.SetEventStatus
            SC_DiagnosticMonitor_MissingControlerHeadlamp_0xC24187_GetDTCOfEvent: operation=DiagnosticMonitor_MissingControlerHeadlamp_0xC24187.GetDTCOfEvent
            SC_DiagnosticMonitor_MissingControlerHeadlamp_0xC24187_GetEventExtendedDataRecordEx: operation=DiagnosticMonitor_MissingControlerHeadlamp_0xC24187.GetEventExtendedDataRecordEx
            SC_DiagnosticMonitor_MissingControlerHeadlamp_0xC24187_GetEventFailed: operation=DiagnosticMonitor_MissingControlerHeadlamp_0xC24187.GetEventFailed
            SC_DiagnosticMonitor_MissingControlerHeadlamp_0xC24187_GetEventFreezeFrameDataEx: operation=DiagnosticMonitor_MissingControlerHeadlamp_0xC24187.GetEventFreezeFrameDataEx
            SC_DiagnosticMonitor_MissingControlerHeadlamp_0xC24187_GetEventStatus: operation=DiagnosticMonitor_MissingControlerHeadlamp_0xC24187.GetEventStatus
            SC_DiagnosticMonitor_MissingControlerHeadlamp_0xC24187_GetEventTested: operation=DiagnosticMonitor_MissingControlerHeadlamp_0xC24187.GetEventTested
            SC_DiagnosticMonitor_MissingControlerHeadlamp_0xC24187_GetEventUdsStatus: operation=DiagnosticMonitor_MissingControlerHeadlamp_0xC24187.GetEventUdsStatus
            SC_DiagnosticMonitor_MissingControlerHeadlamp_0xC24187_GetFaultDetectionCounter: operation=DiagnosticMonitor_MissingControlerHeadlamp_0xC24187.GetFaultDetectionCounter
            SC_DiagnosticMonitor_MissingControlerHeadlamp_0xC24187_ResetEventDebounceStatus: operation=DiagnosticMonitor_MissingControlerHeadlamp_0xC24187.ResetEventDebounceStatus
            SC_DiagnosticMonitor_MissingControlerHeadlamp_0xC24187_ResetEventStatus: operation=DiagnosticMonitor_MissingControlerHeadlamp_0xC24187.ResetEventStatus
            SC_DiagnosticMonitor_MissingControlerHeadlamp_0xC24187_SetEventStatus: operation=DiagnosticMonitor_MissingControlerHeadlamp_0xC24187.SetEventStatus
            SC_DiagnosticMonitor_MissingControllerPedal_0xD00987_GetDTCOfEvent: operation=DiagnosticMonitor_MissingControllerPedal_0xD00987.GetDTCOfEvent
            SC_DiagnosticMonitor_MissingControllerPedal_0xD00987_GetEventExtendedDataRecordEx: operation=DiagnosticMonitor_MissingControllerPedal_0xD00987.GetEventExtendedDataRecordEx
            SC_DiagnosticMonitor_MissingControllerPedal_0xD00987_GetEventFailed: operation=DiagnosticMonitor_MissingControllerPedal_0xD00987.GetEventFailed
            SC_DiagnosticMonitor_MissingControllerPedal_0xD00987_GetEventFreezeFrameDataEx: operation=DiagnosticMonitor_MissingControllerPedal_0xD00987.GetEventFreezeFrameDataEx
            SC_DiagnosticMonitor_MissingControllerPedal_0xD00987_GetEventStatus: operation=DiagnosticMonitor_MissingControllerPedal_0xD00987.GetEventStatus
            SC_DiagnosticMonitor_MissingControllerPedal_0xD00987_GetEventTested: operation=DiagnosticMonitor_MissingControllerPedal_0xD00987.GetEventTested
            SC_DiagnosticMonitor_MissingControllerPedal_0xD00987_GetEventUdsStatus: operation=DiagnosticMonitor_MissingControllerPedal_0xD00987.GetEventUdsStatus
            SC_DiagnosticMonitor_MissingControllerPedal_0xD00987_GetFaultDetectionCounter: operation=DiagnosticMonitor_MissingControllerPedal_0xD00987.GetFaultDetectionCounter
            SC_DiagnosticMonitor_MissingControllerPedal_0xD00987_ResetEventDebounceStatus: operation=DiagnosticMonitor_MissingControllerPedal_0xD00987.ResetEventDebounceStatus
            SC_DiagnosticMonitor_MissingControllerPedal_0xD00987_ResetEventStatus: operation=DiagnosticMonitor_MissingControllerPedal_0xD00987.ResetEventStatus
            SC_DiagnosticMonitor_MissingControllerPedal_0xD00987_SetEventStatus: operation=DiagnosticMonitor_MissingControllerPedal_0xD00987.SetEventStatus
            SC_DiagnosticMonitor_MissingDriverDoorControlModule_0xC19987_GetDTCOfEvent: operation=DiagnosticMonitor_MissingDriverDoorControlModule_0xC19987.GetDTCOfEvent
            SC_DiagnosticMonitor_MissingDriverDoorControlModule_0xC19987_GetEventExtendedDataRecordEx: operation=DiagnosticMonitor_MissingDriverDoorControlModule_0xC19987.GetEventExtendedDataRecordEx
            SC_DiagnosticMonitor_MissingDriverDoorControlModule_0xC19987_GetEventFailed: operation=DiagnosticMonitor_MissingDriverDoorControlModule_0xC19987.GetEventFailed
            SC_DiagnosticMonitor_MissingDriverDoorControlModule_0xC19987_GetEventFreezeFrameDataEx: operation=DiagnosticMonitor_MissingDriverDoorControlModule_0xC19987.GetEventFreezeFrameDataEx
            SC_DiagnosticMonitor_MissingDriverDoorControlModule_0xC19987_GetEventStatus: operation=DiagnosticMonitor_MissingDriverDoorControlModule_0xC19987.GetEventStatus
            SC_DiagnosticMonitor_MissingDriverDoorControlModule_0xC19987_GetEventTested: operation=DiagnosticMonitor_MissingDriverDoorControlModule_0xC19987.GetEventTested
            SC_DiagnosticMonitor_MissingDriverDoorControlModule_0xC19987_GetEventUdsStatus: operation=DiagnosticMonitor_MissingDriverDoorControlModule_0xC19987.GetEventUdsStatus
            SC_DiagnosticMonitor_MissingDriverDoorControlModule_0xC19987_GetFaultDetectionCounter: operation=DiagnosticMonitor_MissingDriverDoorControlModule_0xC19987.GetFaultDetectionCounter
            SC_DiagnosticMonitor_MissingDriverDoorControlModule_0xC19987_ResetEventDebounceStatus: operation=DiagnosticMonitor_MissingDriverDoorControlModule_0xC19987.ResetEventDebounceStatus
            SC_DiagnosticMonitor_MissingDriverDoorControlModule_0xC19987_ResetEventStatus: operation=DiagnosticMonitor_MissingDriverDoorControlModule_0xC19987.ResetEventStatus
            SC_DiagnosticMonitor_MissingDriverDoorControlModule_0xC19987_SetEventStatus: operation=DiagnosticMonitor_MissingDriverDoorControlModule_0xC19987.SetEventStatus
            SC_DiagnosticMonitor_MissingDriverMonitoringSystem_0xC2B387_GetDTCOfEvent: operation=DiagnosticMonitor_MissingDriverMonitoringSystem_0xC2B387.GetDTCOfEvent
            SC_DiagnosticMonitor_MissingDriverMonitoringSystem_0xC2B387_GetEventExtendedDataRecordEx: operation=DiagnosticMonitor_MissingDriverMonitoringSystem_0xC2B387.GetEventExtendedDataRecordEx
            SC_DiagnosticMonitor_MissingDriverMonitoringSystem_0xC2B387_GetEventFailed: operation=DiagnosticMonitor_MissingDriverMonitoringSystem_0xC2B387.GetEventFailed
            SC_DiagnosticMonitor_MissingDriverMonitoringSystem_0xC2B387_GetEventFreezeFrameDataEx: operation=DiagnosticMonitor_MissingDriverMonitoringSystem_0xC2B387.GetEventFreezeFrameDataEx
            SC_DiagnosticMonitor_MissingDriverMonitoringSystem_0xC2B387_GetEventStatus: operation=DiagnosticMonitor_MissingDriverMonitoringSystem_0xC2B387.GetEventStatus
            SC_DiagnosticMonitor_MissingDriverMonitoringSystem_0xC2B387_GetEventTested: operation=DiagnosticMonitor_MissingDriverMonitoringSystem_0xC2B387.GetEventTested
            SC_DiagnosticMonitor_MissingDriverMonitoringSystem_0xC2B387_GetEventUdsStatus: operation=DiagnosticMonitor_MissingDriverMonitoringSystem_0xC2B387.GetEventUdsStatus
            SC_DiagnosticMonitor_MissingDriverMonitoringSystem_0xC2B387_GetFaultDetectionCounter: operation=DiagnosticMonitor_MissingDriverMonitoringSystem_0xC2B387.GetFaultDetectionCounter
            SC_DiagnosticMonitor_MissingDriverMonitoringSystem_0xC2B387_ResetEventDebounceStatus: operation=DiagnosticMonitor_MissingDriverMonitoringSystem_0xC2B387.ResetEventDebounceStatus
            SC_DiagnosticMonitor_MissingDriverMonitoringSystem_0xC2B387_ResetEventStatus: operation=DiagnosticMonitor_MissingDriverMonitoringSystem_0xC2B387.ResetEventStatus
            SC_DiagnosticMonitor_MissingDriverMonitoringSystem_0xC2B387_SetEventStatus: operation=DiagnosticMonitor_MissingDriverMonitoringSystem_0xC2B387.SetEventStatus
            SC_DiagnosticMonitor_MissingElecRegionControlSystemBody_0xD00287_GetDTCOfEvent: operation=DiagnosticMonitor_MissingElecRegionControlSystemBody_0xC14087.GetDTCOfEvent
            SC_DiagnosticMonitor_MissingElecRegionControlSystemBody_0xD00287_GetEventExtendedDataRecordEx: operation=DiagnosticMonitor_MissingElecRegionControlSystemBody_0xC14087.GetEventExtendedDataRecordEx
            SC_DiagnosticMonitor_MissingElecRegionControlSystemBody_0xD00287_GetEventFailed: operation=DiagnosticMonitor_MissingElecRegionControlSystemBody_0xC14087.GetEventFailed
            SC_DiagnosticMonitor_MissingElecRegionControlSystemBody_0xD00287_GetEventFreezeFrameDataEx: operation=DiagnosticMonitor_MissingElecRegionControlSystemBody_0xC14087.GetEventFreezeFrameDataEx
            SC_DiagnosticMonitor_MissingElecRegionControlSystemBody_0xD00287_GetEventStatus: operation=DiagnosticMonitor_MissingElecRegionControlSystemBody_0xC14087.GetEventStatus
            SC_DiagnosticMonitor_MissingElecRegionControlSystemBody_0xD00287_GetEventTested: operation=DiagnosticMonitor_MissingElecRegionControlSystemBody_0xC14087.GetEventTested
            SC_DiagnosticMonitor_MissingElecRegionControlSystemBody_0xD00287_GetEventUdsStatus: operation=DiagnosticMonitor_MissingElecRegionControlSystemBody_0xC14087.GetEventUdsStatus
            SC_DiagnosticMonitor_MissingElecRegionControlSystemBody_0xD00287_GetFaultDetectionCounter: operation=DiagnosticMonitor_MissingElecRegionControlSystemBody_0xC14087.GetFaultDetectionCounter
            SC_DiagnosticMonitor_MissingElecRegionControlSystemBody_0xD00287_ResetEventDebounceStatus: operation=DiagnosticMonitor_MissingElecRegionControlSystemBody_0xC14087.ResetEventDebounceStatus
            SC_DiagnosticMonitor_MissingElecRegionControlSystemBody_0xD00287_ResetEventStatus: operation=DiagnosticMonitor_MissingElecRegionControlSystemBody_0xC14087.ResetEventStatus
            SC_DiagnosticMonitor_MissingElecRegionControlSystemBody_0xD00287_SetEventStatus: operation=DiagnosticMonitor_MissingElecRegionControlSystemBody_0xC14087.SetEventStatus
            SC_DiagnosticMonitor_MissingElectricalStableProgram_0xC12287_GetDTCOfEvent: operation=DiagnosticMonitor_MissingElectricalStableProgram_0xC12287.GetDTCOfEvent
            SC_DiagnosticMonitor_MissingElectricalStableProgram_0xC12287_GetEventExtendedDataRecordEx: operation=DiagnosticMonitor_MissingElectricalStableProgram_0xC12287.GetEventExtendedDataRecordEx
            SC_DiagnosticMonitor_MissingElectricalStableProgram_0xC12287_GetEventFailed: operation=DiagnosticMonitor_MissingElectricalStableProgram_0xC12287.GetEventFailed
            SC_DiagnosticMonitor_MissingElectricalStableProgram_0xC12287_GetEventFreezeFrameDataEx: operation=DiagnosticMonitor_MissingElectricalStableProgram_0xC12287.GetEventFreezeFrameDataEx
            SC_DiagnosticMonitor_MissingElectricalStableProgram_0xC12287_GetEventStatus: operation=DiagnosticMonitor_MissingElectricalStableProgram_0xC12287.GetEventStatus
            SC_DiagnosticMonitor_MissingElectricalStableProgram_0xC12287_GetEventTested: operation=DiagnosticMonitor_MissingElectricalStableProgram_0xC12287.GetEventTested
            SC_DiagnosticMonitor_MissingElectricalStableProgram_0xC12287_GetEventUdsStatus: operation=DiagnosticMonitor_MissingElectricalStableProgram_0xC12287.GetEventUdsStatus
            SC_DiagnosticMonitor_MissingElectricalStableProgram_0xC12287_GetFaultDetectionCounter: operation=DiagnosticMonitor_MissingElectricalStableProgram_0xC12287.GetFaultDetectionCounter
            SC_DiagnosticMonitor_MissingElectricalStableProgram_0xC12287_ResetEventDebounceStatus: operation=DiagnosticMonitor_MissingElectricalStableProgram_0xC12287.ResetEventDebounceStatus
            SC_DiagnosticMonitor_MissingElectricalStableProgram_0xC12287_ResetEventStatus: operation=DiagnosticMonitor_MissingElectricalStableProgram_0xC12287.ResetEventStatus
            SC_DiagnosticMonitor_MissingElectricalStableProgram_0xC12287_SetEventStatus: operation=DiagnosticMonitor_MissingElectricalStableProgram_0xC12287.SetEventStatus
            SC_DiagnosticMonitor_MissingElectricPowerSteeringSystem_0xC13187_GetDTCOfEvent: operation=DiagnosticMonitor_MissingElectricPowerSteeringSystem_0xC13187.GetDTCOfEvent
            SC_DiagnosticMonitor_MissingElectricPowerSteeringSystem_0xC13187_GetEventExtendedDataRecordEx: operation=DiagnosticMonitor_MissingElectricPowerSteeringSystem_0xC13187.GetEventExtendedDataRecordEx
            SC_DiagnosticMonitor_MissingElectricPowerSteeringSystem_0xC13187_GetEventFailed: operation=DiagnosticMonitor_MissingElectricPowerSteeringSystem_0xC13187.GetEventFailed
            SC_DiagnosticMonitor_MissingElectricPowerSteeringSystem_0xC13187_GetEventFreezeFrameDataEx: operation=DiagnosticMonitor_MissingElectricPowerSteeringSystem_0xC13187.GetEventFreezeFrameDataEx
            SC_DiagnosticMonitor_MissingElectricPowerSteeringSystem_0xC13187_GetEventStatus: operation=DiagnosticMonitor_MissingElectricPowerSteeringSystem_0xC13187.GetEventStatus
            SC_DiagnosticMonitor_MissingElectricPowerSteeringSystem_0xC13187_GetEventTested: operation=DiagnosticMonitor_MissingElectricPowerSteeringSystem_0xC13187.GetEventTested
            SC_DiagnosticMonitor_MissingElectricPowerSteeringSystem_0xC13187_GetEventUdsStatus: operation=DiagnosticMonitor_MissingElectricPowerSteeringSystem_0xC13187.GetEventUdsStatus
            SC_DiagnosticMonitor_MissingElectricPowerSteeringSystem_0xC13187_GetFaultDetectionCounter: operation=DiagnosticMonitor_MissingElectricPowerSteeringSystem_0xC13187.GetFaultDetectionCounter
            SC_DiagnosticMonitor_MissingElectricPowerSteeringSystem_0xC13187_ResetEventDebounceStatus: operation=DiagnosticMonitor_MissingElectricPowerSteeringSystem_0xC13187.ResetEventDebounceStatus
            SC_DiagnosticMonitor_MissingElectricPowerSteeringSystem_0xC13187_ResetEventStatus: operation=DiagnosticMonitor_MissingElectricPowerSteeringSystem_0xC13187.ResetEventStatus
            SC_DiagnosticMonitor_MissingElectricPowerSteeringSystem_0xC13187_SetEventStatus: operation=DiagnosticMonitor_MissingElectricPowerSteeringSystem_0xC13187.SetEventStatus
            SC_DiagnosticMonitor_MissingElectronicGerodisc_0xC11587_GetDTCOfEvent: operation=DiagnosticMonitor_MissingElectronicGerodisc_0xC11587.GetDTCOfEvent
            SC_DiagnosticMonitor_MissingElectronicGerodisc_0xC11587_GetEventExtendedDataRecordEx: operation=DiagnosticMonitor_MissingElectronicGerodisc_0xC11587.GetEventExtendedDataRecordEx
            SC_DiagnosticMonitor_MissingElectronicGerodisc_0xC11587_GetEventFailed: operation=DiagnosticMonitor_MissingElectronicGerodisc_0xC11587.GetEventFailed
            SC_DiagnosticMonitor_MissingElectronicGerodisc_0xC11587_GetEventFreezeFrameDataEx: operation=DiagnosticMonitor_MissingElectronicGerodisc_0xC11587.GetEventFreezeFrameDataEx
            SC_DiagnosticMonitor_MissingElectronicGerodisc_0xC11587_GetEventStatus: operation=DiagnosticMonitor_MissingElectronicGerodisc_0xC11587.GetEventStatus
            SC_DiagnosticMonitor_MissingElectronicGerodisc_0xC11587_GetEventTested: operation=DiagnosticMonitor_MissingElectronicGerodisc_0xC11587.GetEventTested
            SC_DiagnosticMonitor_MissingElectronicGerodisc_0xC11587_GetEventUdsStatus: operation=DiagnosticMonitor_MissingElectronicGerodisc_0xC11587.GetEventUdsStatus
            SC_DiagnosticMonitor_MissingElectronicGerodisc_0xC11587_GetFaultDetectionCounter: operation=DiagnosticMonitor_MissingElectronicGerodisc_0xC11587.GetFaultDetectionCounter
            SC_DiagnosticMonitor_MissingElectronicGerodisc_0xC11587_ResetEventDebounceStatus: operation=DiagnosticMonitor_MissingElectronicGerodisc_0xC11587.ResetEventDebounceStatus
            SC_DiagnosticMonitor_MissingElectronicGerodisc_0xC11587_ResetEventStatus: operation=DiagnosticMonitor_MissingElectronicGerodisc_0xC11587.ResetEventStatus
            SC_DiagnosticMonitor_MissingElectronicGerodisc_0xC11587_SetEventStatus: operation=DiagnosticMonitor_MissingElectronicGerodisc_0xC11587.SetEventStatus
            SC_DiagnosticMonitor_MissingFrontPowerBox_0xD10887_GetDTCOfEvent: operation=DiagnosticMonitor_MissingFrontPowerBox_0xD10887.GetDTCOfEvent
            SC_DiagnosticMonitor_MissingFrontPowerBox_0xD10887_GetEventExtendedDataRecordEx: operation=DiagnosticMonitor_MissingFrontPowerBox_0xD10887.GetEventExtendedDataRecordEx
            SC_DiagnosticMonitor_MissingFrontPowerBox_0xD10887_GetEventFailed: operation=DiagnosticMonitor_MissingFrontPowerBox_0xD10887.GetEventFailed
            SC_DiagnosticMonitor_MissingFrontPowerBox_0xD10887_GetEventFreezeFrameDataEx: operation=DiagnosticMonitor_MissingFrontPowerBox_0xD10887.GetEventFreezeFrameDataEx
            SC_DiagnosticMonitor_MissingFrontPowerBox_0xD10887_GetEventStatus: operation=DiagnosticMonitor_MissingFrontPowerBox_0xD10887.GetEventStatus
            SC_DiagnosticMonitor_MissingFrontPowerBox_0xD10887_GetEventTested: operation=DiagnosticMonitor_MissingFrontPowerBox_0xD10887.GetEventTested
            SC_DiagnosticMonitor_MissingFrontPowerBox_0xD10887_GetEventUdsStatus: operation=DiagnosticMonitor_MissingFrontPowerBox_0xD10887.GetEventUdsStatus
            SC_DiagnosticMonitor_MissingFrontPowerBox_0xD10887_GetFaultDetectionCounter: operation=DiagnosticMonitor_MissingFrontPowerBox_0xD10887.GetFaultDetectionCounter
            SC_DiagnosticMonitor_MissingFrontPowerBox_0xD10887_ResetEventDebounceStatus: operation=DiagnosticMonitor_MissingFrontPowerBox_0xD10887.ResetEventDebounceStatus
            SC_DiagnosticMonitor_MissingFrontPowerBox_0xD10887_ResetEventStatus: operation=DiagnosticMonitor_MissingFrontPowerBox_0xD10887.ResetEventStatus
            SC_DiagnosticMonitor_MissingFrontPowerBox_0xD10887_SetEventStatus: operation=DiagnosticMonitor_MissingFrontPowerBox_0xD10887.SetEventStatus
            SC_DiagnosticMonitor_MissingGateway_0xC14687_GetDTCOfEvent: operation=DiagnosticMonitor_MissingGateway_0xC14687.GetDTCOfEvent
            SC_DiagnosticMonitor_MissingGateway_0xC14687_GetEventExtendedDataRecordEx: operation=DiagnosticMonitor_MissingGateway_0xC14687.GetEventExtendedDataRecordEx
            SC_DiagnosticMonitor_MissingGateway_0xC14687_GetEventFailed: operation=DiagnosticMonitor_MissingGateway_0xC14687.GetEventFailed
            SC_DiagnosticMonitor_MissingGateway_0xC14687_GetEventFreezeFrameDataEx: operation=DiagnosticMonitor_MissingGateway_0xC14687.GetEventFreezeFrameDataEx
            SC_DiagnosticMonitor_MissingGateway_0xC14687_GetEventStatus: operation=DiagnosticMonitor_MissingGateway_0xC14687.GetEventStatus
            SC_DiagnosticMonitor_MissingGateway_0xC14687_GetEventTested: operation=DiagnosticMonitor_MissingGateway_0xC14687.GetEventTested
            SC_DiagnosticMonitor_MissingGateway_0xC14687_GetEventUdsStatus: operation=DiagnosticMonitor_MissingGateway_0xC14687.GetEventUdsStatus
            SC_DiagnosticMonitor_MissingGateway_0xC14687_GetFaultDetectionCounter: operation=DiagnosticMonitor_MissingGateway_0xC14687.GetFaultDetectionCounter
            SC_DiagnosticMonitor_MissingGateway_0xC14687_ResetEventDebounceStatus: operation=DiagnosticMonitor_MissingGateway_0xC14687.ResetEventDebounceStatus
            SC_DiagnosticMonitor_MissingGateway_0xC14687_ResetEventStatus: operation=DiagnosticMonitor_MissingGateway_0xC14687.ResetEventStatus
            SC_DiagnosticMonitor_MissingGateway_0xC14687_SetEventStatus: operation=DiagnosticMonitor_MissingGateway_0xC14687.SetEventStatus
            SC_DiagnosticMonitor_MissingHeadUpDisplay_0xC15887_GetDTCOfEvent: operation=DiagnosticMonitor_MissingHeadUpDisplay_0xC15887.GetDTCOfEvent
            SC_DiagnosticMonitor_MissingHeadUpDisplay_0xC15887_GetEventExtendedDataRecordEx: operation=DiagnosticMonitor_MissingHeadUpDisplay_0xC15887.GetEventExtendedDataRecordEx
            SC_DiagnosticMonitor_MissingHeadUpDisplay_0xC15887_GetEventFailed: operation=DiagnosticMonitor_MissingHeadUpDisplay_0xC15887.GetEventFailed
            SC_DiagnosticMonitor_MissingHeadUpDisplay_0xC15887_GetEventFreezeFrameDataEx: operation=DiagnosticMonitor_MissingHeadUpDisplay_0xC15887.GetEventFreezeFrameDataEx
            SC_DiagnosticMonitor_MissingHeadUpDisplay_0xC15887_GetEventStatus: operation=DiagnosticMonitor_MissingHeadUpDisplay_0xC15887.GetEventStatus
            SC_DiagnosticMonitor_MissingHeadUpDisplay_0xC15887_GetEventTested: operation=DiagnosticMonitor_MissingHeadUpDisplay_0xC15887.GetEventTested
            SC_DiagnosticMonitor_MissingHeadUpDisplay_0xC15887_GetEventUdsStatus: operation=DiagnosticMonitor_MissingHeadUpDisplay_0xC15887.GetEventUdsStatus
            SC_DiagnosticMonitor_MissingHeadUpDisplay_0xC15887_GetFaultDetectionCounter: operation=DiagnosticMonitor_MissingHeadUpDisplay_0xC15887.GetFaultDetectionCounter
            SC_DiagnosticMonitor_MissingHeadUpDisplay_0xC15887_ResetEventDebounceStatus: operation=DiagnosticMonitor_MissingHeadUpDisplay_0xC15887.ResetEventDebounceStatus
            SC_DiagnosticMonitor_MissingHeadUpDisplay_0xC15887_ResetEventStatus: operation=DiagnosticMonitor_MissingHeadUpDisplay_0xC15887.ResetEventStatus
            SC_DiagnosticMonitor_MissingHeadUpDisplay_0xC15887_SetEventStatus: operation=DiagnosticMonitor_MissingHeadUpDisplay_0xC15887.SetEventStatus
            SC_DiagnosticMonitor_MissingIntelligentForwardViewCamera_0xC14387_GetDTCOfEvent: operation=DiagnosticMonitor_MissingIntelligentForwardViewCamera_0xC14387.GetDTCOfEvent
            SC_DiagnosticMonitor_MissingIntelligentForwardViewCamera_0xC14387_GetEventExtendedDataRecordEx: operation=DiagnosticMonitor_MissingIntelligentForwardViewCamera_0xC14387.GetEventExtendedDataRecordEx
            SC_DiagnosticMonitor_MissingIntelligentForwardViewCamera_0xC14387_GetEventFailed: operation=DiagnosticMonitor_MissingIntelligentForwardViewCamera_0xC14387.GetEventFailed
            SC_DiagnosticMonitor_MissingIntelligentForwardViewCamera_0xC14387_GetEventFreezeFrameDataEx: operation=DiagnosticMonitor_MissingIntelligentForwardViewCamera_0xC14387.GetEventFreezeFrameDataEx
            SC_DiagnosticMonitor_MissingIntelligentForwardViewCamera_0xC14387_GetEventStatus: operation=DiagnosticMonitor_MissingIntelligentForwardViewCamera_0xC14387.GetEventStatus
            SC_DiagnosticMonitor_MissingIntelligentForwardViewCamera_0xC14387_GetEventTested: operation=DiagnosticMonitor_MissingIntelligentForwardViewCamera_0xC14387.GetEventTested
            SC_DiagnosticMonitor_MissingIntelligentForwardViewCamera_0xC14387_GetEventUdsStatus: operation=DiagnosticMonitor_MissingIntelligentForwardViewCamera_0xC14387.GetEventUdsStatus
            SC_DiagnosticMonitor_MissingIntelligentForwardViewCamera_0xC14387_GetFaultDetectionCounter: operation=DiagnosticMonitor_MissingIntelligentForwardViewCamera_0xC14387.GetFaultDetectionCounter
            SC_DiagnosticMonitor_MissingIntelligentForwardViewCamera_0xC14387_ResetEventDebounceStatus: operation=DiagnosticMonitor_MissingIntelligentForwardViewCamera_0xC14387.ResetEventDebounceStatus
            SC_DiagnosticMonitor_MissingIntelligentForwardViewCamera_0xC14387_ResetEventStatus: operation=DiagnosticMonitor_MissingIntelligentForwardViewCamera_0xC14387.ResetEventStatus
            SC_DiagnosticMonitor_MissingIntelligentForwardViewCamera_0xC14387_SetEventStatus: operation=DiagnosticMonitor_MissingIntelligentForwardViewCamera_0xC14387.SetEventStatus
            SC_DiagnosticMonitor_MissingNextrac_0xC11487_GetDTCOfEvent: operation=DiagnosticMonitor_MissingNextrac_0xC11487.GetDTCOfEvent
            SC_DiagnosticMonitor_MissingNextrac_0xC11487_GetEventExtendedDataRecordEx: operation=DiagnosticMonitor_MissingNextrac_0xC11487.GetEventExtendedDataRecordEx
            SC_DiagnosticMonitor_MissingNextrac_0xC11487_GetEventFailed: operation=DiagnosticMonitor_MissingNextrac_0xC11487.GetEventFailed
            SC_DiagnosticMonitor_MissingNextrac_0xC11487_GetEventFreezeFrameDataEx: operation=DiagnosticMonitor_MissingNextrac_0xC11487.GetEventFreezeFrameDataEx
            SC_DiagnosticMonitor_MissingNextrac_0xC11487_GetEventStatus: operation=DiagnosticMonitor_MissingNextrac_0xC11487.GetEventStatus
            SC_DiagnosticMonitor_MissingNextrac_0xC11487_GetEventTested: operation=DiagnosticMonitor_MissingNextrac_0xC11487.GetEventTested
            SC_DiagnosticMonitor_MissingNextrac_0xC11487_GetEventUdsStatus: operation=DiagnosticMonitor_MissingNextrac_0xC11487.GetEventUdsStatus
            SC_DiagnosticMonitor_MissingNextrac_0xC11487_GetFaultDetectionCounter: operation=DiagnosticMonitor_MissingNextrac_0xC11487.GetFaultDetectionCounter
            SC_DiagnosticMonitor_MissingNextrac_0xC11487_ResetEventDebounceStatus: operation=DiagnosticMonitor_MissingNextrac_0xC11487.ResetEventDebounceStatus
            SC_DiagnosticMonitor_MissingNextrac_0xC11487_ResetEventStatus: operation=DiagnosticMonitor_MissingNextrac_0xC11487.ResetEventStatus
            SC_DiagnosticMonitor_MissingNextrac_0xC11487_SetEventStatus: operation=DiagnosticMonitor_MissingNextrac_0xC11487.SetEventStatus
            SC_DiagnosticMonitor_MissingParkingAssistanceSystem_0xC24387_GetDTCOfEvent: operation=DiagnosticMonitor_MissingParkingAssistanceSystem_0xC24387.GetDTCOfEvent
            SC_DiagnosticMonitor_MissingParkingAssistanceSystem_0xC24387_GetEventExtendedDataRecordEx: operation=DiagnosticMonitor_MissingParkingAssistanceSystem_0xC24387.GetEventExtendedDataRecordEx
            SC_DiagnosticMonitor_MissingParkingAssistanceSystem_0xC24387_GetEventFailed: operation=DiagnosticMonitor_MissingParkingAssistanceSystem_0xC24387.GetEventFailed
            SC_DiagnosticMonitor_MissingParkingAssistanceSystem_0xC24387_GetEventFreezeFrameDataEx: operation=DiagnosticMonitor_MissingParkingAssistanceSystem_0xC24387.GetEventFreezeFrameDataEx
            SC_DiagnosticMonitor_MissingParkingAssistanceSystem_0xC24387_GetEventStatus: operation=DiagnosticMonitor_MissingParkingAssistanceSystem_0xC24387.GetEventStatus
            SC_DiagnosticMonitor_MissingParkingAssistanceSystem_0xC24387_GetEventTested: operation=DiagnosticMonitor_MissingParkingAssistanceSystem_0xC24387.GetEventTested
            SC_DiagnosticMonitor_MissingParkingAssistanceSystem_0xC24387_GetEventUdsStatus: operation=DiagnosticMonitor_MissingParkingAssistanceSystem_0xC24387.GetEventUdsStatus
            SC_DiagnosticMonitor_MissingParkingAssistanceSystem_0xC24387_GetFaultDetectionCounter: operation=DiagnosticMonitor_MissingParkingAssistanceSystem_0xC24387.GetFaultDetectionCounter
            SC_DiagnosticMonitor_MissingParkingAssistanceSystem_0xC24387_ResetEventDebounceStatus: operation=DiagnosticMonitor_MissingParkingAssistanceSystem_0xC24387.ResetEventDebounceStatus
            SC_DiagnosticMonitor_MissingParkingAssistanceSystem_0xC24387_ResetEventStatus: operation=DiagnosticMonitor_MissingParkingAssistanceSystem_0xC24387.ResetEventStatus
            SC_DiagnosticMonitor_MissingParkingAssistanceSystem_0xC24387_SetEventStatus: operation=DiagnosticMonitor_MissingParkingAssistanceSystem_0xC24387.SetEventStatus
            SC_DiagnosticMonitor_MissingPassengerDoorControlModule_0xC20087_GetDTCOfEvent: operation=DiagnosticMonitor_MissingPassengerDoorControlModule_0xC20087.GetDTCOfEvent
            SC_DiagnosticMonitor_MissingPassengerDoorControlModule_0xC20087_GetEventExtendedDataRecordEx: operation=DiagnosticMonitor_MissingPassengerDoorControlModule_0xC20087.GetEventExtendedDataRecordEx
            SC_DiagnosticMonitor_MissingPassengerDoorControlModule_0xC20087_GetEventFailed: operation=DiagnosticMonitor_MissingPassengerDoorControlModule_0xC20087.GetEventFailed
            SC_DiagnosticMonitor_MissingPassengerDoorControlModule_0xC20087_GetEventFreezeFrameDataEx: operation=DiagnosticMonitor_MissingPassengerDoorControlModule_0xC20087.GetEventFreezeFrameDataEx
            SC_DiagnosticMonitor_MissingPassengerDoorControlModule_0xC20087_GetEventStatus: operation=DiagnosticMonitor_MissingPassengerDoorControlModule_0xC20087.GetEventStatus
            SC_DiagnosticMonitor_MissingPassengerDoorControlModule_0xC20087_GetEventTested: operation=DiagnosticMonitor_MissingPassengerDoorControlModule_0xC20087.GetEventTested
            SC_DiagnosticMonitor_MissingPassengerDoorControlModule_0xC20087_GetEventUdsStatus: operation=DiagnosticMonitor_MissingPassengerDoorControlModule_0xC20087.GetEventUdsStatus
            SC_DiagnosticMonitor_MissingPassengerDoorControlModule_0xC20087_GetFaultDetectionCounter: operation=DiagnosticMonitor_MissingPassengerDoorControlModule_0xC20087.GetFaultDetectionCounter
            SC_DiagnosticMonitor_MissingPassengerDoorControlModule_0xC20087_ResetEventDebounceStatus: operation=DiagnosticMonitor_MissingPassengerDoorControlModule_0xC20087.ResetEventDebounceStatus
            SC_DiagnosticMonitor_MissingPassengerDoorControlModule_0xC20087_ResetEventStatus: operation=DiagnosticMonitor_MissingPassengerDoorControlModule_0xC20087.ResetEventStatus
            SC_DiagnosticMonitor_MissingPassengerDoorControlModule_0xC20087_SetEventStatus: operation=DiagnosticMonitor_MissingPassengerDoorControlModule_0xC20087.SetEventStatus
            SC_DiagnosticMonitor_MissingRearPowerBox_0xD10987_GetDTCOfEvent: operation=DiagnosticMonitor_MissingRearPowerBox_0xD10987.GetDTCOfEvent
            SC_DiagnosticMonitor_MissingRearPowerBox_0xD10987_GetEventExtendedDataRecordEx: operation=DiagnosticMonitor_MissingRearPowerBox_0xD10987.GetEventExtendedDataRecordEx
            SC_DiagnosticMonitor_MissingRearPowerBox_0xD10987_GetEventFailed: operation=DiagnosticMonitor_MissingRearPowerBox_0xD10987.GetEventFailed
            SC_DiagnosticMonitor_MissingRearPowerBox_0xD10987_GetEventFreezeFrameDataEx: operation=DiagnosticMonitor_MissingRearPowerBox_0xD10987.GetEventFreezeFrameDataEx
            SC_DiagnosticMonitor_MissingRearPowerBox_0xD10987_GetEventStatus: operation=DiagnosticMonitor_MissingRearPowerBox_0xD10987.GetEventStatus
            SC_DiagnosticMonitor_MissingRearPowerBox_0xD10987_GetEventTested: operation=DiagnosticMonitor_MissingRearPowerBox_0xD10987.GetEventTested
            SC_DiagnosticMonitor_MissingRearPowerBox_0xD10987_GetEventUdsStatus: operation=DiagnosticMonitor_MissingRearPowerBox_0xD10987.GetEventUdsStatus
            SC_DiagnosticMonitor_MissingRearPowerBox_0xD10987_GetFaultDetectionCounter: operation=DiagnosticMonitor_MissingRearPowerBox_0xD10987.GetFaultDetectionCounter
            SC_DiagnosticMonitor_MissingRearPowerBox_0xD10987_ResetEventDebounceStatus: operation=DiagnosticMonitor_MissingRearPowerBox_0xD10987.ResetEventDebounceStatus
            SC_DiagnosticMonitor_MissingRearPowerBox_0xD10987_ResetEventStatus: operation=DiagnosticMonitor_MissingRearPowerBox_0xD10987.ResetEventStatus
            SC_DiagnosticMonitor_MissingRearPowerBox_0xD10987_SetEventStatus: operation=DiagnosticMonitor_MissingRearPowerBox_0xD10987.SetEventStatus
            SC_DiagnosticMonitor_MissingRightRearSideDetectionSystem_0xC23387_GetDTCOfEvent: operation=DiagnosticMonitor_MissingRightRearSideDetectionSystem_0xC23387.GetDTCOfEvent
            SC_DiagnosticMonitor_MissingRightRearSideDetectionSystem_0xC23387_GetEventExtendedDataRecordEx: operation=DiagnosticMonitor_MissingRightRearSideDetectionSystem_0xC23387.GetEventExtendedDataRecordEx
            SC_DiagnosticMonitor_MissingRightRearSideDetectionSystem_0xC23387_GetEventFailed: operation=DiagnosticMonitor_MissingRightRearSideDetectionSystem_0xC23387.GetEventFailed
            SC_DiagnosticMonitor_MissingRightRearSideDetectionSystem_0xC23387_GetEventFreezeFrameDataEx: operation=DiagnosticMonitor_MissingRightRearSideDetectionSystem_0xC23387.GetEventFreezeFrameDataEx
            SC_DiagnosticMonitor_MissingRightRearSideDetectionSystem_0xC23387_GetEventStatus: operation=DiagnosticMonitor_MissingRightRearSideDetectionSystem_0xC23387.GetEventStatus
            SC_DiagnosticMonitor_MissingRightRearSideDetectionSystem_0xC23387_GetEventTested: operation=DiagnosticMonitor_MissingRightRearSideDetectionSystem_0xC23387.GetEventTested
            SC_DiagnosticMonitor_MissingRightRearSideDetectionSystem_0xC23387_GetEventUdsStatus: operation=DiagnosticMonitor_MissingRightRearSideDetectionSystem_0xC23387.GetEventUdsStatus
            SC_DiagnosticMonitor_MissingRightRearSideDetectionSystem_0xC23387_GetFaultDetectionCounter: operation=DiagnosticMonitor_MissingRightRearSideDetectionSystem_0xC23387.GetFaultDetectionCounter
            SC_DiagnosticMonitor_MissingRightRearSideDetectionSystem_0xC23387_ResetEventDebounceStatus: operation=DiagnosticMonitor_MissingRightRearSideDetectionSystem_0xC23387.ResetEventDebounceStatus
            SC_DiagnosticMonitor_MissingRightRearSideDetectionSystem_0xC23387_ResetEventStatus: operation=DiagnosticMonitor_MissingRightRearSideDetectionSystem_0xC23387.ResetEventStatus
            SC_DiagnosticMonitor_MissingRightRearSideDetectionSystem_0xC23387_SetEventStatus: operation=DiagnosticMonitor_MissingRightRearSideDetectionSystem_0xC23387.SetEventStatus
            SC_DiagnosticMonitor_MissingScreenTouchButtonSwitchController_0xD01587_GetDTCOfEvent: operation=DiagnosticMonitor_MissingScreenTouchButtonSwitchController_0xD01587.GetDTCOfEvent
            SC_DiagnosticMonitor_MissingScreenTouchButtonSwitchController_0xD01587_GetEventExtendedDataRecordEx: operation=DiagnosticMonitor_MissingScreenTouchButtonSwitchController_0xD01587.GetEventExtendedDataRecordEx
            SC_DiagnosticMonitor_MissingScreenTouchButtonSwitchController_0xD01587_GetEventFailed: operation=DiagnosticMonitor_MissingScreenTouchButtonSwitchController_0xD01587.GetEventFailed
            SC_DiagnosticMonitor_MissingScreenTouchButtonSwitchController_0xD01587_GetEventFreezeFrameDataEx: operation=DiagnosticMonitor_MissingScreenTouchButtonSwitchController_0xD01587.GetEventFreezeFrameDataEx
            SC_DiagnosticMonitor_MissingScreenTouchButtonSwitchController_0xD01587_GetEventStatus: operation=DiagnosticMonitor_MissingScreenTouchButtonSwitchController_0xD01587.GetEventStatus
            SC_DiagnosticMonitor_MissingScreenTouchButtonSwitchController_0xD01587_GetEventTested: operation=DiagnosticMonitor_MissingScreenTouchButtonSwitchController_0xD01587.GetEventTested
            SC_DiagnosticMonitor_MissingScreenTouchButtonSwitchController_0xD01587_GetEventUdsStatus: operation=DiagnosticMonitor_MissingScreenTouchButtonSwitchController_0xD01587.GetEventUdsStatus
            SC_DiagnosticMonitor_MissingScreenTouchButtonSwitchController_0xD01587_GetFaultDetectionCounter: operation=DiagnosticMonitor_MissingScreenTouchButtonSwitchController_0xD01587.GetFaultDetectionCounter
            SC_DiagnosticMonitor_MissingScreenTouchButtonSwitchController_0xD01587_ResetEventDebounceStatus: operation=DiagnosticMonitor_MissingScreenTouchButtonSwitchController_0xD01587.ResetEventDebounceStatus
            SC_DiagnosticMonitor_MissingScreenTouchButtonSwitchController_0xD01587_ResetEventStatus: operation=DiagnosticMonitor_MissingScreenTouchButtonSwitchController_0xD01587.ResetEventStatus
            SC_DiagnosticMonitor_MissingScreenTouchButtonSwitchController_0xD01587_SetEventStatus: operation=DiagnosticMonitor_MissingScreenTouchButtonSwitchController_0xD01587.SetEventStatus
            SC_DiagnosticMonitor_MissingTelematicsControlBox_0xC19887_GetDTCOfEvent: operation=DiagnosticMonitor_MissingTelematicsControlBox_0xC19887.GetDTCOfEvent
            SC_DiagnosticMonitor_MissingTelematicsControlBox_0xC19887_GetEventExtendedDataRecordEx: operation=DiagnosticMonitor_MissingTelematicsControlBox_0xC19887.GetEventExtendedDataRecordEx
            SC_DiagnosticMonitor_MissingTelematicsControlBox_0xC19887_GetEventFailed: operation=DiagnosticMonitor_MissingTelematicsControlBox_0xC19887.GetEventFailed
            SC_DiagnosticMonitor_MissingTelematicsControlBox_0xC19887_GetEventFreezeFrameDataEx: operation=DiagnosticMonitor_MissingTelematicsControlBox_0xC19887.GetEventFreezeFrameDataEx
            SC_DiagnosticMonitor_MissingTelematicsControlBox_0xC19887_GetEventStatus: operation=DiagnosticMonitor_MissingTelematicsControlBox_0xC19887.GetEventStatus
            SC_DiagnosticMonitor_MissingTelematicsControlBox_0xC19887_GetEventTested: operation=DiagnosticMonitor_MissingTelematicsControlBox_0xC19887.GetEventTested
            SC_DiagnosticMonitor_MissingTelematicsControlBox_0xC19887_GetEventUdsStatus: operation=DiagnosticMonitor_MissingTelematicsControlBox_0xC19887.GetEventUdsStatus
            SC_DiagnosticMonitor_MissingTelematicsControlBox_0xC19887_GetFaultDetectionCounter: operation=DiagnosticMonitor_MissingTelematicsControlBox_0xC19887.GetFaultDetectionCounter
            SC_DiagnosticMonitor_MissingTelematicsControlBox_0xC19887_ResetEventDebounceStatus: operation=DiagnosticMonitor_MissingTelematicsControlBox_0xC19887.ResetEventDebounceStatus
            SC_DiagnosticMonitor_MissingTelematicsControlBox_0xC19887_ResetEventStatus: operation=DiagnosticMonitor_MissingTelematicsControlBox_0xC19887.ResetEventStatus
            SC_DiagnosticMonitor_MissingTelematicsControlBox_0xC19887_SetEventStatus: operation=DiagnosticMonitor_MissingTelematicsControlBox_0xC19887.SetEventStatus
            SC_DiagnosticMonitor_MissingTrailer_0xC14187_GetDTCOfEvent: operation=DiagnosticMonitor_MissingTrailer_0xC14187.GetDTCOfEvent
            SC_DiagnosticMonitor_MissingTrailer_0xC14187_GetEventExtendedDataRecordEx: operation=DiagnosticMonitor_MissingTrailer_0xC14187.GetEventExtendedDataRecordEx
            SC_DiagnosticMonitor_MissingTrailer_0xC14187_GetEventFailed: operation=DiagnosticMonitor_MissingTrailer_0xC14187.GetEventFailed
            SC_DiagnosticMonitor_MissingTrailer_0xC14187_GetEventFreezeFrameDataEx: operation=DiagnosticMonitor_MissingTrailer_0xC14187.GetEventFreezeFrameDataEx
            SC_DiagnosticMonitor_MissingTrailer_0xC14187_GetEventStatus: operation=DiagnosticMonitor_MissingTrailer_0xC14187.GetEventStatus
            SC_DiagnosticMonitor_MissingTrailer_0xC14187_GetEventTested: operation=DiagnosticMonitor_MissingTrailer_0xC14187.GetEventTested
            SC_DiagnosticMonitor_MissingTrailer_0xC14187_GetEventUdsStatus: operation=DiagnosticMonitor_MissingTrailer_0xC14187.GetEventUdsStatus
            SC_DiagnosticMonitor_MissingTrailer_0xC14187_GetFaultDetectionCounter: operation=DiagnosticMonitor_MissingTrailer_0xC14187.GetFaultDetectionCounter
            SC_DiagnosticMonitor_MissingTrailer_0xC14187_ResetEventDebounceStatus: operation=DiagnosticMonitor_MissingTrailer_0xC14187.ResetEventDebounceStatus
            SC_DiagnosticMonitor_MissingTrailer_0xC14187_ResetEventStatus: operation=DiagnosticMonitor_MissingTrailer_0xC14187.ResetEventStatus
            SC_DiagnosticMonitor_MissingTrailer_0xC14187_SetEventStatus: operation=DiagnosticMonitor_MissingTrailer_0xC14187.SetEventStatus
            SC_DiagnosticMonitor_MissingTransmissionControlUntilPTCAN_0xC10187_GetDTCOfEvent: operation=DiagnosticMonitor_MissingTransmissionControlUntilPTCAN_0xC10187.GetDTCOfEvent
            SC_DiagnosticMonitor_MissingTransmissionControlUntilPTCAN_0xC10187_GetEventExtendedDataRecordEx: operation=DiagnosticMonitor_MissingTransmissionControlUntilPTCAN_0xC10187.GetEventExtendedDataRecordEx
            SC_DiagnosticMonitor_MissingTransmissionControlUntilPTCAN_0xC10187_GetEventFailed: operation=DiagnosticMonitor_MissingTransmissionControlUntilPTCAN_0xC10187.GetEventFailed
            SC_DiagnosticMonitor_MissingTransmissionControlUntilPTCAN_0xC10187_GetEventFreezeFrameDataEx: operation=DiagnosticMonitor_MissingTransmissionControlUntilPTCAN_0xC10187.GetEventFreezeFrameDataEx
            SC_DiagnosticMonitor_MissingTransmissionControlUntilPTCAN_0xC10187_GetEventStatus: operation=DiagnosticMonitor_MissingTransmissionControlUntilPTCAN_0xC10187.GetEventStatus
            SC_DiagnosticMonitor_MissingTransmissionControlUntilPTCAN_0xC10187_GetEventTested: operation=DiagnosticMonitor_MissingTransmissionControlUntilPTCAN_0xC10187.GetEventTested
            SC_DiagnosticMonitor_MissingTransmissionControlUntilPTCAN_0xC10187_GetEventUdsStatus: operation=DiagnosticMonitor_MissingTransmissionControlUntilPTCAN_0xC10187.GetEventUdsStatus
            SC_DiagnosticMonitor_MissingTransmissionControlUntilPTCAN_0xC10187_GetFaultDetectionCounter: operation=DiagnosticMonitor_MissingTransmissionControlUntilPTCAN_0xC10187.GetFaultDetectionCounter
            SC_DiagnosticMonitor_MissingTransmissionControlUntilPTCAN_0xC10187_ResetEventDebounceStatus: operation=DiagnosticMonitor_MissingTransmissionControlUntilPTCAN_0xC10187.ResetEventDebounceStatus
            SC_DiagnosticMonitor_MissingTransmissionControlUntilPTCAN_0xC10187_ResetEventStatus: operation=DiagnosticMonitor_MissingTransmissionControlUntilPTCAN_0xC10187.ResetEventStatus
            SC_DiagnosticMonitor_MissingTransmissionControlUntilPTCAN_0xC10187_SetEventStatus: operation=DiagnosticMonitor_MissingTransmissionControlUntilPTCAN_0xC10187.SetEventStatus
            SC_DiagnosticMonitor_MissingTyrePressureMonitoringSystem_0xC12787_GetDTCOfEvent: operation=DiagnosticMonitor_MissingTyrePressureMonitoringSystem_0xC12787.GetDTCOfEvent
            SC_DiagnosticMonitor_MissingTyrePressureMonitoringSystem_0xC12787_GetEventExtendedDataRecordEx: operation=DiagnosticMonitor_MissingTyrePressureMonitoringSystem_0xC12787.GetEventExtendedDataRecordEx
            SC_DiagnosticMonitor_MissingTyrePressureMonitoringSystem_0xC12787_GetEventFailed: operation=DiagnosticMonitor_MissingTyrePressureMonitoringSystem_0xC12787.GetEventFailed
            SC_DiagnosticMonitor_MissingTyrePressureMonitoringSystem_0xC12787_GetEventFreezeFrameDataEx: operation=DiagnosticMonitor_MissingTyrePressureMonitoringSystem_0xC12787.GetEventFreezeFrameDataEx
            SC_DiagnosticMonitor_MissingTyrePressureMonitoringSystem_0xC12787_GetEventStatus: operation=DiagnosticMonitor_MissingTyrePressureMonitoringSystem_0xC12787.GetEventStatus
            SC_DiagnosticMonitor_MissingTyrePressureMonitoringSystem_0xC12787_GetEventTested: operation=DiagnosticMonitor_MissingTyrePressureMonitoringSystem_0xC12787.GetEventTested
            SC_DiagnosticMonitor_MissingTyrePressureMonitoringSystem_0xC12787_GetEventUdsStatus: operation=DiagnosticMonitor_MissingTyrePressureMonitoringSystem_0xC12787.GetEventUdsStatus
            SC_DiagnosticMonitor_MissingTyrePressureMonitoringSystem_0xC12787_GetFaultDetectionCounter: operation=DiagnosticMonitor_MissingTyrePressureMonitoringSystem_0xC12787.GetFaultDetectionCounter
            SC_DiagnosticMonitor_MissingTyrePressureMonitoringSystem_0xC12787_ResetEventDebounceStatus: operation=DiagnosticMonitor_MissingTyrePressureMonitoringSystem_0xC12787.ResetEventDebounceStatus
            SC_DiagnosticMonitor_MissingTyrePressureMonitoringSystem_0xC12787_ResetEventStatus: operation=DiagnosticMonitor_MissingTyrePressureMonitoringSystem_0xC12787.ResetEventStatus
            SC_DiagnosticMonitor_MissingTyrePressureMonitoringSystem_0xC12787_SetEventStatus: operation=DiagnosticMonitor_MissingTyrePressureMonitoringSystem_0xC12787.SetEventStatus
            SC_DiagnosticMonitor_MissingWirelessPowerCharger_0xD02987_GetDTCOfEvent: operation=DiagnosticMonitor_MissingWirelessPowerCharger_0xD02987.GetDTCOfEvent
            SC_DiagnosticMonitor_MissingWirelessPowerCharger_0xD02987_GetEventExtendedDataRecordEx: operation=DiagnosticMonitor_MissingWirelessPowerCharger_0xD02987.GetEventExtendedDataRecordEx
            SC_DiagnosticMonitor_MissingWirelessPowerCharger_0xD02987_GetEventFailed: operation=DiagnosticMonitor_MissingWirelessPowerCharger_0xD02987.GetEventFailed
            SC_DiagnosticMonitor_MissingWirelessPowerCharger_0xD02987_GetEventFreezeFrameDataEx: operation=DiagnosticMonitor_MissingWirelessPowerCharger_0xD02987.GetEventFreezeFrameDataEx
            SC_DiagnosticMonitor_MissingWirelessPowerCharger_0xD02987_GetEventStatus: operation=DiagnosticMonitor_MissingWirelessPowerCharger_0xD02987.GetEventStatus
            SC_DiagnosticMonitor_MissingWirelessPowerCharger_0xD02987_GetEventTested: operation=DiagnosticMonitor_MissingWirelessPowerCharger_0xD02987.GetEventTested
            SC_DiagnosticMonitor_MissingWirelessPowerCharger_0xD02987_GetEventUdsStatus: operation=DiagnosticMonitor_MissingWirelessPowerCharger_0xD02987.GetEventUdsStatus
            SC_DiagnosticMonitor_MissingWirelessPowerCharger_0xD02987_GetFaultDetectionCounter: operation=DiagnosticMonitor_MissingWirelessPowerCharger_0xD02987.GetFaultDetectionCounter
            SC_DiagnosticMonitor_MissingWirelessPowerCharger_0xD02987_ResetEventDebounceStatus: operation=DiagnosticMonitor_MissingWirelessPowerCharger_0xD02987.ResetEventDebounceStatus
            SC_DiagnosticMonitor_MissingWirelessPowerCharger_0xD02987_ResetEventStatus: operation=DiagnosticMonitor_MissingWirelessPowerCharger_0xD02987.ResetEventStatus
            SC_DiagnosticMonitor_MissingWirelessPowerCharger_0xD02987_SetEventStatus: operation=DiagnosticMonitor_MissingWirelessPowerCharger_0xD02987.SetEventStatus
            SC_DiagnosticMonitor_MissingElectricParkBrakecontroller_0xC12887_SetEventStatus: operation=DiagnosticMonitor_MissingElectricParkBrakecontroller_0xC12887.SetEventStatus
            SC_DiagnosticMonitor_MissingBatteryManagementSystem_0xC11187_GetDTCOfEvent: operation=DiagnosticMonitor_MissingBatteryManagementSystem_0xC11187.GetDTCOfEvent
            SC_DiagnosticMonitor_MissingBatteryManagementSystem_0xC11187_GetEventExtendedDataRecordEx: operation=DiagnosticMonitor_MissingBatteryManagementSystem_0xC11187.GetEventExtendedDataRecordEx
            SC_DiagnosticMonitor_MissingBatteryManagementSystem_0xC11187_GetEventFailed: operation=DiagnosticMonitor_MissingBatteryManagementSystem_0xC11187.GetEventFailed
            SC_DiagnosticMonitor_MissingBatteryManagementSystem_0xC11187_GetEventFreezeFrameDataEx: operation=DiagnosticMonitor_MissingBatteryManagementSystem_0xC11187.GetEventFreezeFrameDataEx
            SC_DiagnosticMonitor_MissingBatteryManagementSystem_0xC11187_GetEventStatus: operation=DiagnosticMonitor_MissingBatteryManagementSystem_0xC11187.GetEventStatus
            SC_DiagnosticMonitor_MissingBatteryManagementSystem_0xC11187_GetEventTested: operation=DiagnosticMonitor_MissingBatteryManagementSystem_0xC11187.GetEventTested
            SC_DiagnosticMonitor_MissingBatteryManagementSystem_0xC11187_GetEventUdsStatus: operation=DiagnosticMonitor_MissingBatteryManagementSystem_0xC11187.GetEventUdsStatus
            SC_DiagnosticMonitor_MissingBatteryManagementSystem_0xC11187_GetFaultDetectionCounter: operation=DiagnosticMonitor_MissingBatteryManagementSystem_0xC11187.GetFaultDetectionCounter
            SC_DiagnosticMonitor_MissingBatteryManagementSystem_0xC11187_ResetEventDebounceStatus: operation=DiagnosticMonitor_MissingBatteryManagementSystem_0xC11187.ResetEventDebounceStatus
            SC_DiagnosticMonitor_MissingBatteryManagementSystem_0xC11187_ResetEventStatus: operation=DiagnosticMonitor_MissingBatteryManagementSystem_0xC11187.ResetEventStatus
            SC_DiagnosticMonitor_MissingBatteryManagementSystem_0xC11187_SetEventStatus: operation=DiagnosticMonitor_MissingBatteryManagementSystem_0xC11187.SetEventStatus
            SC_DiagnosticMonitor_MissingDriverSeatMemorymodule_0xC20887_GetDTCOfEvent: operation=DiagnosticMonitor_MissingDriverSeatMemorymodule_0xC20887.GetDTCOfEvent
            SC_DiagnosticMonitor_MissingDriverSeatMemorymodule_0xC20887_GetEventExtendedDataRecordEx: operation=DiagnosticMonitor_MissingDriverSeatMemorymodule_0xC20887.GetEventExtendedDataRecordEx
            SC_DiagnosticMonitor_MissingDriverSeatMemorymodule_0xC20887_GetEventFailed: operation=DiagnosticMonitor_MissingDriverSeatMemorymodule_0xC20887.GetEventFailed
            SC_DiagnosticMonitor_MissingDriverSeatMemorymodule_0xC20887_GetEventFreezeFrameDataEx: operation=DiagnosticMonitor_MissingDriverSeatMemorymodule_0xC20887.GetEventFreezeFrameDataEx
            SC_DiagnosticMonitor_MissingDriverSeatMemorymodule_0xC20887_GetEventStatus: operation=DiagnosticMonitor_MissingDriverSeatMemorymodule_0xC20887.GetEventStatus
            SC_DiagnosticMonitor_MissingDriverSeatMemorymodule_0xC20887_GetEventTested: operation=DiagnosticMonitor_MissingDriverSeatMemorymodule_0xC20887.GetEventTested
            SC_DiagnosticMonitor_MissingDriverSeatMemorymodule_0xC20887_GetEventUdsStatus: operation=DiagnosticMonitor_MissingDriverSeatMemorymodule_0xC20887.GetEventUdsStatus
            SC_DiagnosticMonitor_MissingDriverSeatMemorymodule_0xC20887_GetFaultDetectionCounter: operation=DiagnosticMonitor_MissingDriverSeatMemorymodule_0xC20887.GetFaultDetectionCounter
            SC_DiagnosticMonitor_MissingDriverSeatMemorymodule_0xC20887_ResetEventDebounceStatus: operation=DiagnosticMonitor_MissingDriverSeatMemorymodule_0xC20887.ResetEventDebounceStatus
            SC_DiagnosticMonitor_MissingDriverSeatMemorymodule_0xC20887_ResetEventStatus: operation=DiagnosticMonitor_MissingDriverSeatMemorymodule_0xC20887.ResetEventStatus
            SC_DiagnosticMonitor_MissingDriverSeatMemorymodule_0xC20887_SetEventStatus: operation=DiagnosticMonitor_MissingDriverSeatMemorymodule_0xC20887.SetEventStatus
            SC_DiagnosticMonitor_MissingElectricParkBrakecontroller_0xC12887_GetDTCOfEvent: operation=DiagnosticMonitor_MissingElectricParkBrakecontroller_0xC12887.GetDTCOfEvent
            SC_DiagnosticMonitor_MissingElectricParkBrakecontroller_0xC12887_GetEventExtendedDataRecordEx: operation=DiagnosticMonitor_MissingElectricParkBrakecontroller_0xC12887.GetEventExtendedDataRecordEx
            SC_DiagnosticMonitor_MissingElectricParkBrakecontroller_0xC12887_GetEventFailed: operation=DiagnosticMonitor_MissingElectricParkBrakecontroller_0xC12887.GetEventFailed
            SC_DiagnosticMonitor_MissingElectricParkBrakecontroller_0xC12887_GetEventFreezeFrameDataEx: operation=DiagnosticMonitor_MissingElectricParkBrakecontroller_0xC12887.GetEventFreezeFrameDataEx
            SC_DiagnosticMonitor_MissingElectricParkBrakecontroller_0xC12887_GetEventStatus: operation=DiagnosticMonitor_MissingElectricParkBrakecontroller_0xC12887.GetEventStatus
            SC_DiagnosticMonitor_MissingElectricParkBrakecontroller_0xC12887_GetEventTested: operation=DiagnosticMonitor_MissingElectricParkBrakecontroller_0xC12887.GetEventTested
            SC_DiagnosticMonitor_MissingElectricParkBrakecontroller_0xC12887_GetEventUdsStatus: operation=DiagnosticMonitor_MissingElectricParkBrakecontroller_0xC12887.GetEventUdsStatus
            SC_DiagnosticMonitor_MissingElectricParkBrakecontroller_0xC12887_GetFaultDetectionCounter: operation=DiagnosticMonitor_MissingElectricParkBrakecontroller_0xC12887.GetFaultDetectionCounter
            SC_DiagnosticMonitor_MissingElectricParkBrakecontroller_0xC12887_ResetEventDebounceStatus: operation=DiagnosticMonitor_MissingElectricParkBrakecontroller_0xC12887.ResetEventDebounceStatus
            SC_DiagnosticMonitor_MissingElectricParkBrakecontroller_0xC12887_ResetEventStatus: operation=DiagnosticMonitor_MissingElectricParkBrakecontroller_0xC12887.ResetEventStatus
            SC_DiagnosticMonitor_MissingHybridVehicleControlUnitVehiclecontrolunit_HCCAN_0xC29387_GetDTCOfEvent: operation=DiagnosticMonitor_MissingHybridVehicleControlUnitVehiclecontrolunit_HCCAN_0xC29387.GetDTCOfEvent
            SC_DiagnosticMonitor_MissingHybridVehicleControlUnitVehiclecontrolunit_HCCAN_0xC29387_GetEventExtendedDataRecordEx: operation=DiagnosticMonitor_MissingHybridVehicleControlUnitVehiclecontrolunit_HCCAN_0xC29387.GetEventExtendedDataRecordEx
            SC_DiagnosticMonitor_MissingHybridVehicleControlUnitVehiclecontrolunit_HCCAN_0xC29387_GetEventFailed: operation=DiagnosticMonitor_MissingHybridVehicleControlUnitVehiclecontrolunit_HCCAN_0xC29387.GetEventFailed
            SC_DiagnosticMonitor_MissingHybridVehicleControlUnitVehiclecontrolunit_HCCAN_0xC29387_GetEventFreezeFrameDataEx: operation=DiagnosticMonitor_MissingHybridVehicleControlUnitVehiclecontrolunit_HCCAN_0xC29387.GetEventFreezeFrameDataEx
            SC_DiagnosticMonitor_MissingHybridVehicleControlUnitVehiclecontrolunit_HCCAN_0xC29387_GetEventStatus: operation=DiagnosticMonitor_MissingHybridVehicleControlUnitVehiclecontrolunit_HCCAN_0xC29387.GetEventStatus
            SC_DiagnosticMonitor_MissingHybridVehicleControlUnitVehiclecontrolunit_HCCAN_0xC29387_GetEventTested: operation=DiagnosticMonitor_MissingHybridVehicleControlUnitVehiclecontrolunit_HCCAN_0xC29387.GetEventTested
            SC_DiagnosticMonitor_MissingHybridVehicleControlUnitVehiclecontrolunit_HCCAN_0xC29387_GetEventUdsStatus: operation=DiagnosticMonitor_MissingHybridVehicleControlUnitVehiclecontrolunit_HCCAN_0xC29387.GetEventUdsStatus
            SC_DiagnosticMonitor_MissingHybridVehicleControlUnitVehiclecontrolunit_HCCAN_0xC29387_GetFaultDetectionCounter: operation=DiagnosticMonitor_MissingHybridVehicleControlUnitVehiclecontrolunit_HCCAN_0xC29387.GetFaultDetectionCounter
            SC_DiagnosticMonitor_MissingHybridVehicleControlUnitVehiclecontrolunit_HCCAN_0xC29387_ResetEventDebounceStatus: operation=DiagnosticMonitor_MissingHybridVehicleControlUnitVehiclecontrolunit_HCCAN_0xC29387.ResetEventDebounceStatus
            SC_DiagnosticMonitor_MissingHybridVehicleControlUnitVehiclecontrolunit_HCCAN_0xC29387_ResetEventStatus: operation=DiagnosticMonitor_MissingHybridVehicleControlUnitVehiclecontrolunit_HCCAN_0xC29387.ResetEventStatus
            SC_DiagnosticMonitor_MissingHybridVehicleControlUnitVehiclecontrolunit_HCCAN_0xC29387_SetEventStatus: operation=DiagnosticMonitor_MissingHybridVehicleControlUnitVehiclecontrolunit_HCCAN_0xC29387.SetEventStatus
            SC_DiagnosticMonitor_MissingHybridVehicleControlUnitVehiclecontrolunit_PTCAN_0xD02687_GetDTCOfEvent: operation=DiagnosticMonitor_MissingHybridVehicleControlUnitVehiclecontrolunit_PTCAN_0xD02687.GetDTCOfEvent
            SC_DiagnosticMonitor_MissingHybridVehicleControlUnitVehiclecontrolunit_PTCAN_0xD02687_GetEventExtendedDataRecordEx: operation=DiagnosticMonitor_MissingHybridVehicleControlUnitVehiclecontrolunit_PTCAN_0xD02687.GetEventExtendedDataRecordEx
            SC_DiagnosticMonitor_MissingHybridVehicleControlUnitVehiclecontrolunit_PTCAN_0xD02687_GetEventFailed: operation=DiagnosticMonitor_MissingHybridVehicleControlUnitVehiclecontrolunit_PTCAN_0xD02687.GetEventFailed
            SC_DiagnosticMonitor_MissingHybridVehicleControlUnitVehiclecontrolunit_PTCAN_0xD02687_GetEventFreezeFrameDataEx: operation=DiagnosticMonitor_MissingHybridVehicleControlUnitVehiclecontrolunit_PTCAN_0xD02687.GetEventFreezeFrameDataEx
            SC_DiagnosticMonitor_MissingHybridVehicleControlUnitVehiclecontrolunit_PTCAN_0xD02687_GetEventStatus: operation=DiagnosticMonitor_MissingHybridVehicleControlUnitVehiclecontrolunit_PTCAN_0xD02687.GetEventStatus
            SC_DiagnosticMonitor_MissingHybridVehicleControlUnitVehiclecontrolunit_PTCAN_0xD02687_GetEventTested: operation=DiagnosticMonitor_MissingHybridVehicleControlUnitVehiclecontrolunit_PTCAN_0xD02687.GetEventTested
            SC_DiagnosticMonitor_MissingHybridVehicleControlUnitVehiclecontrolunit_PTCAN_0xD02687_GetEventUdsStatus: operation=DiagnosticMonitor_MissingHybridVehicleControlUnitVehiclecontrolunit_PTCAN_0xD02687.GetEventUdsStatus
            SC_DiagnosticMonitor_MissingHybridVehicleControlUnitVehiclecontrolunit_PTCAN_0xD02687_GetFaultDetectionCounter: operation=DiagnosticMonitor_MissingHybridVehicleControlUnitVehiclecontrolunit_PTCAN_0xD02687.GetFaultDetectionCounter
            SC_DiagnosticMonitor_MissingHybridVehicleControlUnitVehiclecontrolunit_PTCAN_0xD02687_ResetEventDebounceStatus: operation=DiagnosticMonitor_MissingHybridVehicleControlUnitVehiclecontrolunit_PTCAN_0xD02687.ResetEventDebounceStatus
            SC_DiagnosticMonitor_MissingHybridVehicleControlUnitVehiclecontrolunit_PTCAN_0xD02687_ResetEventStatus: operation=DiagnosticMonitor_MissingHybridVehicleControlUnitVehiclecontrolunit_PTCAN_0xD02687.ResetEventStatus
            SC_DiagnosticMonitor_MissingHybridVehicleControlUnitVehiclecontrolunit_PTCAN_0xD02687_SetEventStatus: operation=DiagnosticMonitor_MissingHybridVehicleControlUnitVehiclecontrolunit_PTCAN_0xD02687.SetEventStatus
            SC_DiagnosticMonitor_MissingIbooster_0xC25E87_GetDTCOfEvent: operation=DiagnosticMonitor_MissingIbooster_0xC25E87.GetDTCOfEvent
            SC_DiagnosticMonitor_MissingIbooster_0xC25E87_GetEventExtendedDataRecordEx: operation=DiagnosticMonitor_MissingIbooster_0xC25E87.GetEventExtendedDataRecordEx
            SC_DiagnosticMonitor_MissingIbooster_0xC25E87_GetEventFailed: operation=DiagnosticMonitor_MissingIbooster_0xC25E87.GetEventFailed
            SC_DiagnosticMonitor_MissingIbooster_0xC25E87_GetEventFreezeFrameDataEx: operation=DiagnosticMonitor_MissingIbooster_0xC25E87.GetEventFreezeFrameDataEx
            SC_DiagnosticMonitor_MissingIbooster_0xC25E87_GetEventStatus: operation=DiagnosticMonitor_MissingIbooster_0xC25E87.GetEventStatus
            SC_DiagnosticMonitor_MissingIbooster_0xC25E87_GetEventTested: operation=DiagnosticMonitor_MissingIbooster_0xC25E87.GetEventTested
            SC_DiagnosticMonitor_MissingIbooster_0xC25E87_GetEventUdsStatus: operation=DiagnosticMonitor_MissingIbooster_0xC25E87.GetEventUdsStatus
            SC_DiagnosticMonitor_MissingIbooster_0xC25E87_GetFaultDetectionCounter: operation=DiagnosticMonitor_MissingIbooster_0xC25E87.GetFaultDetectionCounter
            SC_DiagnosticMonitor_MissingIbooster_0xC25E87_ResetEventDebounceStatus: operation=DiagnosticMonitor_MissingIbooster_0xC25E87.ResetEventDebounceStatus
            SC_DiagnosticMonitor_MissingIbooster_0xC25E87_ResetEventStatus: operation=DiagnosticMonitor_MissingIbooster_0xC25E87.ResetEventStatus
            SC_DiagnosticMonitor_MissingIbooster_0xC25E87_SetEventStatus: operation=DiagnosticMonitor_MissingIbooster_0xC25E87.SetEventStatus
            SC_DiagnosticMonitor_MissingIntelligentDrivingController_Level2_0xC15C87_GetDTCOfEvent: operation=DiagnosticMonitor_MissingIntelligentDrivingController_Level2_0xC15C87.GetDTCOfEvent
            SC_DiagnosticMonitor_MissingIntelligentDrivingController_Level2_0xC15C87_GetEventExtendedDataRecordEx: operation=DiagnosticMonitor_MissingIntelligentDrivingController_Level2_0xC15C87.GetEventExtendedDataRecordEx
            SC_DiagnosticMonitor_MissingIntelligentDrivingController_Level2_0xC15C87_GetEventFailed: operation=DiagnosticMonitor_MissingIntelligentDrivingController_Level2_0xC15C87.GetEventFailed
            SC_DiagnosticMonitor_MissingIntelligentDrivingController_Level2_0xC15C87_GetEventFreezeFrameDataEx: operation=DiagnosticMonitor_MissingIntelligentDrivingController_Level2_0xC15C87.GetEventFreezeFrameDataEx
            SC_DiagnosticMonitor_MissingIntelligentDrivingController_Level2_0xC15C87_GetEventStatus: operation=DiagnosticMonitor_MissingIntelligentDrivingController_Level2_0xC15C87.GetEventStatus
            SC_DiagnosticMonitor_MissingIntelligentDrivingController_Level2_0xC15C87_GetEventTested: operation=DiagnosticMonitor_MissingIntelligentDrivingController_Level2_0xC15C87.GetEventTested
            SC_DiagnosticMonitor_MissingIntelligentDrivingController_Level2_0xC15C87_GetEventUdsStatus: operation=DiagnosticMonitor_MissingIntelligentDrivingController_Level2_0xC15C87.GetEventUdsStatus
            SC_DiagnosticMonitor_MissingIntelligentDrivingController_Level2_0xC15C87_GetFaultDetectionCounter: operation=DiagnosticMonitor_MissingIntelligentDrivingController_Level2_0xC15C87.GetFaultDetectionCounter
            SC_DiagnosticMonitor_MissingIntelligentDrivingController_Level2_0xC15C87_ResetEventDebounceStatus: operation=DiagnosticMonitor_MissingIntelligentDrivingController_Level2_0xC15C87.ResetEventDebounceStatus
            SC_DiagnosticMonitor_MissingIntelligentDrivingController_Level2_0xC15C87_ResetEventStatus: operation=DiagnosticMonitor_MissingIntelligentDrivingController_Level2_0xC15C87.ResetEventStatus
            SC_DiagnosticMonitor_MissingIntelligentDrivingController_Level2_0xC15C87_SetEventStatus: operation=DiagnosticMonitor_MissingIntelligentDrivingController_Level2_0xC15C87.SetEventStatus
            SC_DiagnosticMonitor_MissingOnboardcharger_0xC1BB87_GetDTCOfEvent: operation=DiagnosticMonitor_MissingOnboardcharger_0xC1BB87.GetDTCOfEvent
            SC_DiagnosticMonitor_MissingOnboardcharger_0xC1BB87_GetEventExtendedDataRecordEx: operation=DiagnosticMonitor_MissingOnboardcharger_0xC1BB87.GetEventExtendedDataRecordEx
            SC_DiagnosticMonitor_MissingOnboardcharger_0xC1BB87_GetEventFailed: operation=DiagnosticMonitor_MissingOnboardcharger_0xC1BB87.GetEventFailed
            SC_DiagnosticMonitor_MissingOnboardcharger_0xC1BB87_GetEventFreezeFrameDataEx: operation=DiagnosticMonitor_MissingOnboardcharger_0xC1BB87.GetEventFreezeFrameDataEx
            SC_DiagnosticMonitor_MissingOnboardcharger_0xC1BB87_GetEventStatus: operation=DiagnosticMonitor_MissingOnboardcharger_0xC1BB87.GetEventStatus
            SC_DiagnosticMonitor_MissingOnboardcharger_0xC1BB87_GetEventTested: operation=DiagnosticMonitor_MissingOnboardcharger_0xC1BB87.GetEventTested
            SC_DiagnosticMonitor_MissingOnboardcharger_0xC1BB87_GetEventUdsStatus: operation=DiagnosticMonitor_MissingOnboardcharger_0xC1BB87.GetEventUdsStatus
            SC_DiagnosticMonitor_MissingOnboardcharger_0xC1BB87_GetFaultDetectionCounter: operation=DiagnosticMonitor_MissingOnboardcharger_0xC1BB87.GetFaultDetectionCounter
            SC_DiagnosticMonitor_MissingOnboardcharger_0xC1BB87_ResetEventDebounceStatus: operation=DiagnosticMonitor_MissingOnboardcharger_0xC1BB87.ResetEventDebounceStatus
            SC_DiagnosticMonitor_MissingOnboardcharger_0xC1BB87_ResetEventStatus: operation=DiagnosticMonitor_MissingOnboardcharger_0xC1BB87.ResetEventStatus
            SC_DiagnosticMonitor_MissingOnboardcharger_0xC1BB87_SetEventStatus: operation=DiagnosticMonitor_MissingOnboardcharger_0xC1BB87.SetEventStatus
            SC_DiagnosticMonitor_MissingPowerLiftGatemodule_0xC23087_GetDTCOfEvent: operation=DiagnosticMonitor_MissingPowerLiftGatemodule_0xC23087.GetDTCOfEvent
            SC_DiagnosticMonitor_MissingPowerLiftGatemodule_0xC23087_GetEventExtendedDataRecordEx: operation=DiagnosticMonitor_MissingPowerLiftGatemodule_0xC23087.GetEventExtendedDataRecordEx
            SC_DiagnosticMonitor_MissingPowerLiftGatemodule_0xC23087_GetEventFailed: operation=DiagnosticMonitor_MissingPowerLiftGatemodule_0xC23087.GetEventFailed
            SC_DiagnosticMonitor_MissingPowerLiftGatemodule_0xC23087_GetEventFreezeFrameDataEx: operation=DiagnosticMonitor_MissingPowerLiftGatemodule_0xC23087.GetEventFreezeFrameDataEx
            SC_DiagnosticMonitor_MissingPowerLiftGatemodule_0xC23087_GetEventStatus: operation=DiagnosticMonitor_MissingPowerLiftGatemodule_0xC23087.GetEventStatus
            SC_DiagnosticMonitor_MissingPowerLiftGatemodule_0xC23087_GetEventTested: operation=DiagnosticMonitor_MissingPowerLiftGatemodule_0xC23087.GetEventTested
            SC_DiagnosticMonitor_MissingPowerLiftGatemodule_0xC23087_GetEventUdsStatus: operation=DiagnosticMonitor_MissingPowerLiftGatemodule_0xC23087.GetEventUdsStatus
            SC_DiagnosticMonitor_MissingPowerLiftGatemodule_0xC23087_GetFaultDetectionCounter: operation=DiagnosticMonitor_MissingPowerLiftGatemodule_0xC23087.GetFaultDetectionCounter
            SC_DiagnosticMonitor_MissingPowerLiftGatemodule_0xC23087_ResetEventDebounceStatus: operation=DiagnosticMonitor_MissingPowerLiftGatemodule_0xC23087.ResetEventDebounceStatus
            SC_DiagnosticMonitor_MissingPowerLiftGatemodule_0xC23087_ResetEventStatus: operation=DiagnosticMonitor_MissingPowerLiftGatemodule_0xC23087.ResetEventStatus
            SC_DiagnosticMonitor_MissingPowerLiftGatemodule_0xC23087_SetEventStatus: operation=DiagnosticMonitor_MissingPowerLiftGatemodule_0xC23087.SetEventStatus
            SC_DiagnosticMonitor_MissingPrePretensionerMechatronicIntegrated_0xD10B87_GetDTCOfEvent: operation=DiagnosticMonitor_MissingPrePretensionerMechatronicIntegrated_0xD10B87.GetDTCOfEvent
            SC_DiagnosticMonitor_MissingPrePretensionerMechatronicIntegrated_0xD10B87_GetEventExtendedDataRecordEx: operation=DiagnosticMonitor_MissingPrePretensionerMechatronicIntegrated_0xD10B87.GetEventExtendedDataRecordEx
            SC_DiagnosticMonitor_MissingPrePretensionerMechatronicIntegrated_0xD10B87_GetEventFailed: operation=DiagnosticMonitor_MissingPrePretensionerMechatronicIntegrated_0xD10B87.GetEventFailed
            SC_DiagnosticMonitor_MissingPrePretensionerMechatronicIntegrated_0xD10B87_GetEventFreezeFrameDataEx: operation=DiagnosticMonitor_MissingPrePretensionerMechatronicIntegrated_0xD10B87.GetEventFreezeFrameDataEx
            SC_DiagnosticMonitor_MissingPrePretensionerMechatronicIntegrated_0xD10B87_GetEventStatus: operation=DiagnosticMonitor_MissingPrePretensionerMechatronicIntegrated_0xD10B87.GetEventStatus
            SC_DiagnosticMonitor_MissingPrePretensionerMechatronicIntegrated_0xD10B87_GetEventTested: operation=DiagnosticMonitor_MissingPrePretensionerMechatronicIntegrated_0xD10B87.GetEventTested
            SC_DiagnosticMonitor_MissingPrePretensionerMechatronicIntegrated_0xD10B87_GetEventUdsStatus: operation=DiagnosticMonitor_MissingPrePretensionerMechatronicIntegrated_0xD10B87.GetEventUdsStatus
            SC_DiagnosticMonitor_MissingPrePretensionerMechatronicIntegrated_0xD10B87_GetFaultDetectionCounter: operation=DiagnosticMonitor_MissingPrePretensionerMechatronicIntegrated_0xD10B87.GetFaultDetectionCounter
            SC_DiagnosticMonitor_MissingPrePretensionerMechatronicIntegrated_0xD10B87_ResetEventDebounceStatus: operation=DiagnosticMonitor_MissingPrePretensionerMechatronicIntegrated_0xD10B87.ResetEventDebounceStatus
            SC_DiagnosticMonitor_MissingPrePretensionerMechatronicIntegrated_0xD10B87_ResetEventStatus: operation=DiagnosticMonitor_MissingPrePretensionerMechatronicIntegrated_0xD10B87.ResetEventStatus
            SC_DiagnosticMonitor_MissingPrePretensionerMechatronicIntegrated_0xD10B87_SetEventStatus: operation=DiagnosticMonitor_MissingPrePretensionerMechatronicIntegrated_0xD10B87.SetEventStatus
            SC_DiagnosticMonitor_MissingRearHeatVentSeatModule_0xC24787_GetDTCOfEvent: operation=DiagnosticMonitor_MissingRearHeatVentSeatModule_0xC24787.GetDTCOfEvent
            SC_DiagnosticMonitor_MissingRearHeatVentSeatModule_0xC24787_GetEventExtendedDataRecordEx: operation=DiagnosticMonitor_MissingRearHeatVentSeatModule_0xC24787.GetEventExtendedDataRecordEx
            SC_DiagnosticMonitor_MissingRearHeatVentSeatModule_0xC24787_GetEventFailed: operation=DiagnosticMonitor_MissingRearHeatVentSeatModule_0xC24787.GetEventFailed
            SC_DiagnosticMonitor_MissingRearHeatVentSeatModule_0xC24787_GetEventFreezeFrameDataEx: operation=DiagnosticMonitor_MissingRearHeatVentSeatModule_0xC24787.GetEventFreezeFrameDataEx
            SC_DiagnosticMonitor_MissingRearHeatVentSeatModule_0xC24787_GetEventStatus: operation=DiagnosticMonitor_MissingRearHeatVentSeatModule_0xC24787.GetEventStatus
            SC_DiagnosticMonitor_MissingRearHeatVentSeatModule_0xC24787_GetEventTested: operation=DiagnosticMonitor_MissingRearHeatVentSeatModule_0xC24787.GetEventTested
            SC_DiagnosticMonitor_MissingRearHeatVentSeatModule_0xC24787_GetEventUdsStatus: operation=DiagnosticMonitor_MissingRearHeatVentSeatModule_0xC24787.GetEventUdsStatus
            SC_DiagnosticMonitor_MissingRearHeatVentSeatModule_0xC24787_GetFaultDetectionCounter: operation=DiagnosticMonitor_MissingRearHeatVentSeatModule_0xC24787.GetFaultDetectionCounter
            SC_DiagnosticMonitor_MissingRearHeatVentSeatModule_0xC24787_ResetEventDebounceStatus: operation=DiagnosticMonitor_MissingRearHeatVentSeatModule_0xC24787.ResetEventDebounceStatus
            SC_DiagnosticMonitor_MissingRearHeatVentSeatModule_0xC24787_ResetEventStatus: operation=DiagnosticMonitor_MissingRearHeatVentSeatModule_0xC24787.ResetEventStatus
            SC_DiagnosticMonitor_MissingRearHeatVentSeatModule_0xC24787_SetEventStatus: operation=DiagnosticMonitor_MissingRearHeatVentSeatModule_0xC24787.SetEventStatus
            SC_DiagnosticMonitor_MissingRightHeadlampControlModule_0xC24287_GetDTCOfEvent: operation=DiagnosticMonitor_MissingRightHeadlampControlModule_0xC24287.GetDTCOfEvent
            SC_DiagnosticMonitor_MissingRightHeadlampControlModule_0xC24287_GetEventExtendedDataRecordEx: operation=DiagnosticMonitor_MissingRightHeadlampControlModule_0xC24287.GetEventExtendedDataRecordEx
            SC_DiagnosticMonitor_MissingRightHeadlampControlModule_0xC24287_GetEventFailed: operation=DiagnosticMonitor_MissingRightHeadlampControlModule_0xC24287.GetEventFailed
            SC_DiagnosticMonitor_MissingRightHeadlampControlModule_0xC24287_GetEventFreezeFrameDataEx: operation=DiagnosticMonitor_MissingRightHeadlampControlModule_0xC24287.GetEventFreezeFrameDataEx
            SC_DiagnosticMonitor_MissingRightHeadlampControlModule_0xC24287_GetEventStatus: operation=DiagnosticMonitor_MissingRightHeadlampControlModule_0xC24287.GetEventStatus
            SC_DiagnosticMonitor_MissingRightHeadlampControlModule_0xC24287_GetEventTested: operation=DiagnosticMonitor_MissingRightHeadlampControlModule_0xC24287.GetEventTested
            SC_DiagnosticMonitor_MissingRightHeadlampControlModule_0xC24287_GetEventUdsStatus: operation=DiagnosticMonitor_MissingRightHeadlampControlModule_0xC24287.GetEventUdsStatus
            SC_DiagnosticMonitor_MissingRightHeadlampControlModule_0xC24287_GetFaultDetectionCounter: operation=DiagnosticMonitor_MissingRightHeadlampControlModule_0xC24287.GetFaultDetectionCounter
            SC_DiagnosticMonitor_MissingRightHeadlampControlModule_0xC24287_ResetEventDebounceStatus: operation=DiagnosticMonitor_MissingRightHeadlampControlModule_0xC24287.ResetEventDebounceStatus
            SC_DiagnosticMonitor_MissingRightHeadlampControlModule_0xC24287_ResetEventStatus: operation=DiagnosticMonitor_MissingRightHeadlampControlModule_0xC24287.ResetEventStatus
            SC_DiagnosticMonitor_MissingRightHeadlampControlModule_0xC24287_SetEventStatus: operation=DiagnosticMonitor_MissingRightHeadlampControlModule_0xC24287.SetEventStatus
            SC_DiagnosticMonitor_missingAdaptiveCruiseControlsystemRadarControlModule_0xC10487_GetDTCOfEvent: operation=DiagnosticMonitor_missingAdaptiveCruiseControlsystemRadarControlModule_0xC10487.GetDTCOfEvent
            SC_DiagnosticMonitor_missingAdaptiveCruiseControlsystemRadarControlModule_0xC10487_GetEventExtendedDataRecordEx: operation=DiagnosticMonitor_missingAdaptiveCruiseControlsystemRadarControlModule_0xC10487.GetEventExtendedDataRecordEx
            SC_DiagnosticMonitor_missingAdaptiveCruiseControlsystemRadarControlModule_0xC10487_GetEventFailed: operation=DiagnosticMonitor_missingAdaptiveCruiseControlsystemRadarControlModule_0xC10487.GetEventFailed
            SC_DiagnosticMonitor_missingAdaptiveCruiseControlsystemRadarControlModule_0xC10487_GetEventFreezeFrameDataEx: operation=DiagnosticMonitor_missingAdaptiveCruiseControlsystemRadarControlModule_0xC10487.GetEventFreezeFrameDataEx
            SC_DiagnosticMonitor_missingAdaptiveCruiseControlsystemRadarControlModule_0xC10487_GetEventStatus: operation=DiagnosticMonitor_missingAdaptiveCruiseControlsystemRadarControlModule_0xC10487.GetEventStatus
            SC_DiagnosticMonitor_missingAdaptiveCruiseControlsystemRadarControlModule_0xC10487_GetEventTested: operation=DiagnosticMonitor_missingAdaptiveCruiseControlsystemRadarControlModule_0xC10487.GetEventTested
            SC_DiagnosticMonitor_missingAdaptiveCruiseControlsystemRadarControlModule_0xC10487_GetEventUdsStatus: operation=DiagnosticMonitor_missingAdaptiveCruiseControlsystemRadarControlModule_0xC10487.GetEventUdsStatus
            SC_DiagnosticMonitor_missingAdaptiveCruiseControlsystemRadarControlModule_0xC10487_GetFaultDetectionCounter: operation=DiagnosticMonitor_missingAdaptiveCruiseControlsystemRadarControlModule_0xC10487.GetFaultDetectionCounter
            SC_DiagnosticMonitor_missingAdaptiveCruiseControlsystemRadarControlModule_0xC10487_ResetEventDebounceStatus: operation=DiagnosticMonitor_missingAdaptiveCruiseControlsystemRadarControlModule_0xC10487.ResetEventDebounceStatus
            SC_DiagnosticMonitor_missingAdaptiveCruiseControlsystemRadarControlModule_0xC10487_ResetEventStatus: operation=DiagnosticMonitor_missingAdaptiveCruiseControlsystemRadarControlModule_0xC10487.ResetEventStatus
            SC_DiagnosticMonitor_missingAdaptiveCruiseControlsystemRadarControlModule_0xC10487_SetEventStatus: operation=DiagnosticMonitor_missingAdaptiveCruiseControlsystemRadarControlModule_0xC10487.SetEventStatus
            SC_DiagnosticMonitor_missingRightCornerRadar_0xC2B587_GetDTCOfEvent: operation=DiagnosticMonitor_missingRightCornerRadar_0xC2B587.GetDTCOfEvent
            SC_DiagnosticMonitor_missingRightCornerRadar_0xC2B587_GetEventExtendedDataRecordEx: operation=DiagnosticMonitor_missingRightCornerRadar_0xC2B587.GetEventExtendedDataRecordEx
            SC_DiagnosticMonitor_missingRightCornerRadar_0xC2B587_GetEventFailed: operation=DiagnosticMonitor_missingRightCornerRadar_0xC2B587.GetEventFailed
            SC_DiagnosticMonitor_missingRightCornerRadar_0xC2B587_GetEventFreezeFrameDataEx: operation=DiagnosticMonitor_missingRightCornerRadar_0xC2B587.GetEventFreezeFrameDataEx
            SC_DiagnosticMonitor_missingRightCornerRadar_0xC2B587_GetEventStatus: operation=DiagnosticMonitor_missingRightCornerRadar_0xC2B587.GetEventStatus
            SC_DiagnosticMonitor_missingRightCornerRadar_0xC2B587_GetEventTested: operation=DiagnosticMonitor_missingRightCornerRadar_0xC2B587.GetEventTested
            SC_DiagnosticMonitor_missingRightCornerRadar_0xC2B587_GetEventUdsStatus: operation=DiagnosticMonitor_missingRightCornerRadar_0xC2B587.GetEventUdsStatus
            SC_DiagnosticMonitor_missingRightCornerRadar_0xC2B587_GetFaultDetectionCounter: operation=DiagnosticMonitor_missingRightCornerRadar_0xC2B587.GetFaultDetectionCounter
            SC_DiagnosticMonitor_missingRightCornerRadar_0xC2B587_ResetEventDebounceStatus: operation=DiagnosticMonitor_missingRightCornerRadar_0xC2B587.ResetEventDebounceStatus
            SC_DiagnosticMonitor_missingRightCornerRadar_0xC2B587_ResetEventStatus: operation=DiagnosticMonitor_missingRightCornerRadar_0xC2B587.ResetEventStatus
            SC_DiagnosticMonitor_missingRightCornerRadar_0xC2B587_SetEventStatus: operation=DiagnosticMonitor_missingRightCornerRadar_0xC2B587.SetEventStatus
            SC_DiagnosticMonitor_missingSeatControlModule_0xC24687_GetDTCOfEvent: operation=DiagnosticMonitor_missingSeatControlModule_0xC24687.GetDTCOfEvent
            SC_DiagnosticMonitor_missingSeatControlModule_0xC24687_GetEventExtendedDataRecordEx: operation=DiagnosticMonitor_missingSeatControlModule_0xC24687.GetEventExtendedDataRecordEx
            SC_DiagnosticMonitor_missingSeatControlModule_0xC24687_GetEventFailed: operation=DiagnosticMonitor_missingSeatControlModule_0xC24687.GetEventFailed
            SC_DiagnosticMonitor_missingSeatControlModule_0xC24687_GetEventFreezeFrameDataEx: operation=DiagnosticMonitor_missingSeatControlModule_0xC24687.GetEventFreezeFrameDataEx
            SC_DiagnosticMonitor_missingSeatControlModule_0xC24687_GetEventStatus: operation=DiagnosticMonitor_missingSeatControlModule_0xC24687.GetEventStatus
            SC_DiagnosticMonitor_missingSeatControlModule_0xC24687_GetEventTested: operation=DiagnosticMonitor_missingSeatControlModule_0xC24687.GetEventTested
            SC_DiagnosticMonitor_missingSeatControlModule_0xC24687_GetEventUdsStatus: operation=DiagnosticMonitor_missingSeatControlModule_0xC24687.GetEventUdsStatus
            SC_DiagnosticMonitor_missingSeatControlModule_0xC24687_GetFaultDetectionCounter: operation=DiagnosticMonitor_missingSeatControlModule_0xC24687.GetFaultDetectionCounter
            SC_DiagnosticMonitor_missingSeatControlModule_0xC24687_ResetEventDebounceStatus: operation=DiagnosticMonitor_missingSeatControlModule_0xC24687.ResetEventDebounceStatus
            SC_DiagnosticMonitor_missingSeatControlModule_0xC24687_ResetEventStatus: operation=DiagnosticMonitor_missingSeatControlModule_0xC24687.ResetEventStatus
            SC_DiagnosticMonitor_missingSeatControlModule_0xC24687_SetEventStatus: operation=DiagnosticMonitor_missingSeatControlModule_0xC24687.SetEventStatus
            SC_rpCS_IPC_TransmitSignal_Callback: operation=rpCS_IPC_TransmitSignal.Callback
            SC_rpCS_IPC_Tx_E2E_CanMsg_HUT_IP2_Callback: operation=rpCS_IPC_Tx_E2E_CanMsg_HUT_IP2.Callback
            SC_rpCS_IPC_API_SetEventTxSignalBuffer_Operation: operation=rpCS_IPC_API_SetEventTxSignalBuffer.Operation
            SC_rpCS_IPC_Tx_E2E_CanMsg_HUT32_CallBack: operation=rpCS_IPC_Tx_E2E_CanMsg_HUT32.CallBack
            SC_rpCS_ComEx_SendSignal: operation=rpCS_ComEx.SendSignal
            SC_rpCS_ComEx_GetRxE2EStatus: operation=rpCS_ComEx.GetRxE2EStatus
            SC_rpCS_ComEx_ReceiveSignal: operation=rpCS_ComEx.ReceiveSignal
            SC_DiagnosticMonitor_MissingDepthOfWaterDetectionModule_0xD12387_GetDTCOfEvent: operation=DiagnosticMonitor_MissingDepthOfWaterDetectionModule_0xD12387.GetDTCOfEvent
            SC_DiagnosticMonitor_MissingDepthOfWaterDetectionModule_0xD12387_GetEventExtendedDataRecordEx: operation=DiagnosticMonitor_MissingDepthOfWaterDetectionModule_0xD12387.GetEventExtendedDataRecordEx
            SC_DiagnosticMonitor_MissingDepthOfWaterDetectionModule_0xD12387_GetEventFailed: operation=DiagnosticMonitor_MissingDepthOfWaterDetectionModule_0xD12387.GetEventFailed
            SC_DiagnosticMonitor_MissingDepthOfWaterDetectionModule_0xD12387_GetEventFreezeFrameDataEx: operation=DiagnosticMonitor_MissingDepthOfWaterDetectionModule_0xD12387.GetEventFreezeFrameDataEx
            SC_DiagnosticMonitor_MissingDepthOfWaterDetectionModule_0xD12387_GetEventStatus: operation=DiagnosticMonitor_MissingDepthOfWaterDetectionModule_0xD12387.GetEventStatus
            SC_DiagnosticMonitor_MissingDepthOfWaterDetectionModule_0xD12387_GetEventTested: operation=DiagnosticMonitor_MissingDepthOfWaterDetectionModule_0xD12387.GetEventTested
            SC_DiagnosticMonitor_MissingDepthOfWaterDetectionModule_0xD12387_GetEventUdsStatus: operation=DiagnosticMonitor_MissingDepthOfWaterDetectionModule_0xD12387.GetEventUdsStatus
            SC_DiagnosticMonitor_MissingDepthOfWaterDetectionModule_0xD12387_GetFaultDetectionCounter: operation=DiagnosticMonitor_MissingDepthOfWaterDetectionModule_0xD12387.GetFaultDetectionCounter
            SC_DiagnosticMonitor_MissingDepthOfWaterDetectionModule_0xD12387_ResetEventDebounceStatus: operation=DiagnosticMonitor_MissingDepthOfWaterDetectionModule_0xD12387.ResetEventDebounceStatus
            SC_DiagnosticMonitor_MissingDepthOfWaterDetectionModule_0xD12387_ResetEventStatus: operation=DiagnosticMonitor_MissingDepthOfWaterDetectionModule_0xD12387.ResetEventStatus
            SC_DiagnosticMonitor_MissingDepthOfWaterDetectionModule_0xD12387_SetEventStatus: operation=DiagnosticMonitor_MissingDepthOfWaterDetectionModule_0xD12387.SetEventStatus
            SC_cpCS_IRTC_Service_UTC2PerpetualCalendar: operation=cpCS_IRTC_Service.UTC2PerpetualCalendar
            SC_DiagnosticMonitor_AbnormalWakeupSleep_0xF01200_GetDTCOfEvent: operation=DiagnosticMonitor_AbnormalWakeupSleep_0xF01200.GetDTCOfEvent
            SC_DiagnosticMonitor_AbnormalWakeupSleep_0xF01200_GetEventExtendedDataRecordEx: operation=DiagnosticMonitor_AbnormalWakeupSleep_0xF01200.GetEventExtendedDataRecordEx
            SC_DiagnosticMonitor_AbnormalWakeupSleep_0xF01200_GetEventFailed: operation=DiagnosticMonitor_AbnormalWakeupSleep_0xF01200.GetEventFailed
            SC_DiagnosticMonitor_AbnormalWakeupSleep_0xF01200_GetEventFreezeFrameDataEx: operation=DiagnosticMonitor_AbnormalWakeupSleep_0xF01200.GetEventFreezeFrameDataEx
            SC_DiagnosticMonitor_AbnormalWakeupSleep_0xF01200_GetEventStatus: operation=DiagnosticMonitor_AbnormalWakeupSleep_0xF01200.GetEventStatus
            SC_DiagnosticMonitor_AbnormalWakeupSleep_0xF01200_GetEventTested: operation=DiagnosticMonitor_AbnormalWakeupSleep_0xF01200.GetEventTested
            SC_DiagnosticMonitor_AbnormalWakeupSleep_0xF01200_GetEventUdsStatus: operation=DiagnosticMonitor_AbnormalWakeupSleep_0xF01200.GetEventUdsStatus
            SC_DiagnosticMonitor_AbnormalWakeupSleep_0xF01200_GetFaultDetectionCounter: operation=DiagnosticMonitor_AbnormalWakeupSleep_0xF01200.GetFaultDetectionCounter
            SC_DiagnosticMonitor_AbnormalWakeupSleep_0xF01200_ResetEventDebounceStatus: operation=DiagnosticMonitor_AbnormalWakeupSleep_0xF01200.ResetEventDebounceStatus
            SC_DiagnosticMonitor_AbnormalWakeupSleep_0xF01200_ResetEventStatus: operation=DiagnosticMonitor_AbnormalWakeupSleep_0xF01200.ResetEventStatus
            SC_DiagnosticMonitor_AbnormalWakeupSleep_0xF01200_SetEventStatus: operation=DiagnosticMonitor_AbnormalWakeupSleep_0xF01200.SetEventStatus
            SC_NvMService_AC2_SRBS_NvBlockNeed_AbnormalWakeupSleepRecords_GetErrorStatus: operation=NvMService_AC2_SRBS_NvBlockNeed_AbnormalWakeupSleepRecords.GetErrorStatus
            SC_NvMService_AC2_SRBS_NvBlockNeed_AbnormalWakeupSleepRecords_ReadBlock: operation=NvMService_AC2_SRBS_NvBlockNeed_AbnormalWakeupSleepRecords.ReadBlock
            SC_NvMService_AC2_SRBS_NvBlockNeed_AbnormalWakeupSleepRecords_SetRamBlockStatus: operation=NvMService_AC2_SRBS_NvBlockNeed_AbnormalWakeupSleepRecords.SetRamBlockStatus
            SC_NvMService_AC2_SRBS_NvBlockNeed_AbnormalWakeupSleepRecords_WriteBlock: operation=NvMService_AC2_SRBS_NvBlockNeed_AbnormalWakeupSleepRecords.WriteBlock
            SC_NvMService_AC2_SRBS_NvBlockNeed_ActiveWUCounter_GetErrorStatus: operation=NvMService_AC2_SRBS_NvBlockNeed_ActiveWUCounter.GetErrorStatus
            SC_NvMService_AC2_SRBS_NvBlockNeed_ActiveWUCounter_ReadBlock: operation=NvMService_AC2_SRBS_NvBlockNeed_ActiveWUCounter.ReadBlock
            SC_NvMService_AC2_SRBS_NvBlockNeed_ActiveWUCounter_SetRamBlockStatus: operation=NvMService_AC2_SRBS_NvBlockNeed_ActiveWUCounter.SetRamBlockStatus
            SC_NvMService_AC2_SRBS_NvBlockNeed_ActiveWUCounter_WriteBlock: operation=NvMService_AC2_SRBS_NvBlockNeed_ActiveWUCounter.WriteBlock
        CNA_SignalSet
        CanServer_MainFunction_5ms
          data-receive-point-by-arguments:
            access REC_ClearDTC_Service0x14_StatusFlag: accessed-variable=ClearDTC_Service0x14.StatusFlag
          sync call SC_DiagnosticMonitor_BusOff_0xC07388_SetEventStatus: operation=DiagnosticMonitor_BusOff_0xC07388.SetEventStatus
        CanFrameCounter_Can_ECM2_Counter
        CanFrameCounter_Can_ESP_FD2_Counter
        CanFrameCounter_Can_ABS3_Counter
        CNA_SignalCallBack
        CNA_SignalSetNoTrigger
        CNA_SignalSet_U8N
        CNA_SignalGroupSet
        Can_Server_AbnormalWakeupSleepRecord_Get
        NvMNotifyJobFinished_NvBlockNeed_ActiveWUCounter_JobFinished
        NvMNotifyJobFinished_NvBlockNeed_AbnormalWakeupSleepRecords_JobFinished
      swc service dependency NvBlockNeed_ActiveWUCounter
        assigned-datas:
          role=ramBlock, used-data-element=NvBlockNeed_ActiveWUCounter_MirrorBlock
          role=defaultValue, used-parameter-element=NvBlockNeed_ActiveWUCounter_DefaultValue
        assigned-ports:
          port-prototype=NvMNotifyJobFinished_NvBlockNeed_ActiveWUCounter, role=NvMNotifyJobFinished
          port-prototype=NvMService_AC2_SRBS_NvBlockNeed_ActiveWUCounter, role=NvMService_AC2_SRBS
        service-needs:
          nv block needs NvBlockNeed_ActiveWUCounter: n-data-sets=0, ram-block-status-control=API, reliability=NO-PROTECTION, restore-at-start=true, store-at-shutdown=true
      swc service dependency NvBlockNeed_AbnormalWakeupSleepRecords
        assigned-datas:
          role=ramBlock, used-data-element=NvBlockNeed_AbnormalWakeupSleepRecords_MirrorBlock
          role=defaultValue, used-parameter-element=NvBlockNeed_AbnormalWakeupSleepRecords_DefaultValue
        assigned-ports:
          port-prototype=NvMNotifyJobFinished_NvBlockNeed_AbnormalWakeupSleepRecords, role=NvMNotifyJobFinished
          port-prototype=NvMService_AC2_SRBS_NvBlockNeed_AbnormalWakeupSleepRecords, role=NvMService_AC2_SRBS
        service-needs:
          nv block needs NvBlockNeed_AbnormalWakeupSleepRecords: n-data-sets=0, ram-block-status-control=API, reliability=NO-PROTECTION, restore-at-start=true, store-at-shutdown=true
      shared-parameters:
        parameter data prototype NvBlockNeed_ActiveWUCounter_DefaultValue: sw-calibration-access=READ-WRITE, type=uint8, init-value=0
        parameter data prototype NvBlockNeed_AbnormalWakeupSleepRecords_DefaultValue: sw-calibration-access=READ-WRITE, type=A_80Bytes, init-value=80 x 0
